VERSION ""

NS_ :

BS_:

BU_: ACM AMP BCM DIAG_TEST EMCM ESEM ETM HMSM IPC LBSS RBSS TBM TTM
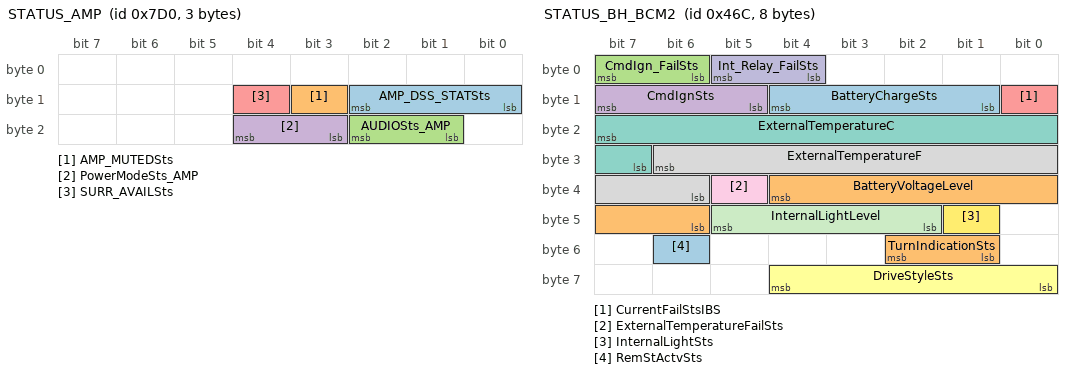
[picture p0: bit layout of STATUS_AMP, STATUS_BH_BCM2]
BO_ 2000 STATUS_AMP: 3 AMP
 SG_ AMP_DSS_STATSts : 10|3@0+ (1,0) [0|7] "" ETM
 SG_ AMP_MUTEDSts : 11|1@0+ (1,0) [0|1] "" ETM
 SG_ AUDIOSts_AMP : 18|2@0+ (1,0) [0|3] "" ETM
 SG_ PowerModeSts_AMP : 20|2@0+ (1,0) [0|3] "" BCM
 SG_ SURR_AVAILSts : 12|1@0+ (1,0) [0|1] "" ETM

BO_ 854 STATUS_BH_BCM1: 8 BCM
 SG_ BonnetSts : 26|1@0+ (1,0) [0|1] "-" ETM,IPC
 SG_ BrakeFluidLevelSts : 25|1@0+ (1,0) [0|1] "-" ETM
 SG_ BrakePadWearSts : 43|1@0+ (1,0) [0|1] "-" IPC
 SG_ BrakePedalSwitchNOSts : 36|1@0+ (1,0) [0|1] "-" ETM
 SG_ DoorLockLastElSts : 57|2@0+ (1,0) [0|3] "" ETM
 SG_ DriverDoorSts : 31|1@0+ (1,0) [0|1] "-" ACM,ETM,HMSM,IPC
 SG_ ESLLockFailSts_Indication : 55|1@0+ (1,0) [0|1] "-" IPC
 SG_ ESLUnlockFailSts_Indication : 54|1@0+ (1,0) [0|1] "-" IPC
 SG_ FrontWiperMoveSts : 42|1@0+ (1,0) [0|1] "" ACM
 SG_ FuelLevel : 7|8@0+ (1,0) [0|255] "%" ETM
 SG_ FuelLevelFailSts : 15|1@0+ (1,0) [0|1] "-" ETM
 SG_ FWindShieldFailSts : 51|1@0+ (1,0) [0|1] "-" IPC
 SG_ IMMOCodeWarningLightSts : 14|7@0+ (1,0) [0|18] "-" IPC
 SG_ LHRDoorSts : 29|1@0+ (1,0) [0|1] "-" ACM,ETM,IPC
 SG_ LowFuelWarningSts : 39|1@0+ (1,0) [0|1] "-" IPC
 SG_ MoveWheelSts : 52|1@0+ (1,0) [0|1] "-" IPC
 SG_ NightAndDaySensorFailSts : 33|1@0+ (1,0) [0|1] "" IPC
 SG_ OperationalModeSts : 23|4@0+ (1,0) [0|15] "" ACM,AMP,EMCM,ESEM,ETM,HMSM,LBSS,RBSS,TBM,TTM
 SG_ ParkBrakeSts : 24|1@0+ (1,0) [0|1] "-" LBSS,RBSS
 SG_ PowerModeSts : 19|2@0+ (1,0) [0|3] "" ACM,AMP,EMCM,ESEM,ETM,TBM
 SG_ PsngrDoorSts : 30|1@0+ (1,0) [0|1] "-" ACM,ETM,IPC
 SG_ RainSensorFailSts : 38|1@0+ (1,0) [0|1] "-" IPC
 SG_ RearTrunkEnableLastElSts : 27|1@0+ (1,0) [0|1] "-" ETM
 SG_ RHatchSts : 35|1@0+ (1,0) [0|1] "-" ACM,ETM,IPC
 SG_ RHRDoorSts : 28|1@0+ (1,0) [0|1] "-" ACM,ETM,IPC
 SG_ SysEOLSts : 34|1@0+ (1,0) [0|1] "-" IPC
 SG_ WarningKeyInSts : 37|1@0+ (1,0) [0|1] "" IPC

BO_ 1132 STATUS_BH_BCM2: 8 BCM
 SG_ BatteryChargeSts : 12|4@0+ (5,40) [40|110] "%" Vector__XXX
 SG_ BatteryVoltageLevel : 36|7@0+ (0.16,0) [0|18] "Volt" ACM,LBSS,RBSS
 SG_ CmdIgn_FailSts : 7|2@0+ (1,0) [0|3] "" ACM,AMP,EMCM,ESEM,ETM,HMSM,LBSS,RBSS,TBM,TTM
 SG_ CmdIgnSts : 15|3@0+ (1,0) [0|7] "" ACM,AMP,EMCM,ESEM,ETM,HMSM,LBSS,RBSS,TBM,TTM
 SG_ CurrentFailStsIBS : 8|1@0+ (1,0) [0|1] "-" Vector__XXX
 SG_ DriveStyleSts : 60|5@0+ (1,0) [0|31] "-" ESEM,ETM,IPC
 SG_ ExternalTemperatureC : 23|9@0+ (0.5,-85) [-85|170] "°C" ACM,ETM,IPC
 SG_ ExternalTemperatureF : 30|9@0+ (1,-121) [-121|389] "°F" ETM,IPC
 SG_ ExternalTemperatureFailSts : 37|1@0+ (1,0) [0|1] "-" ACM,ETM,IPC
 SG_ Int_Relay_FailSts : 5|2@0+ (1,0) [0|3] "" Vector__XXX
 SG_ InternalLightLevel : 45|4@0+ (1,0) [0|15] "" ACM,EMCM,ETM
 SG_ InternalLightSts : 41|1@0+ (1,0) [0|1] "" ACM,EMCM,ETM,LBSS,RBSS
 SG_ RemStActvSts : 54|1@0+ (1,0) [0|1] "" ACM
 SG_ TurnIndicationSts : 50|2@0+ (1,0) [0|3] "" LBSS,RBSS

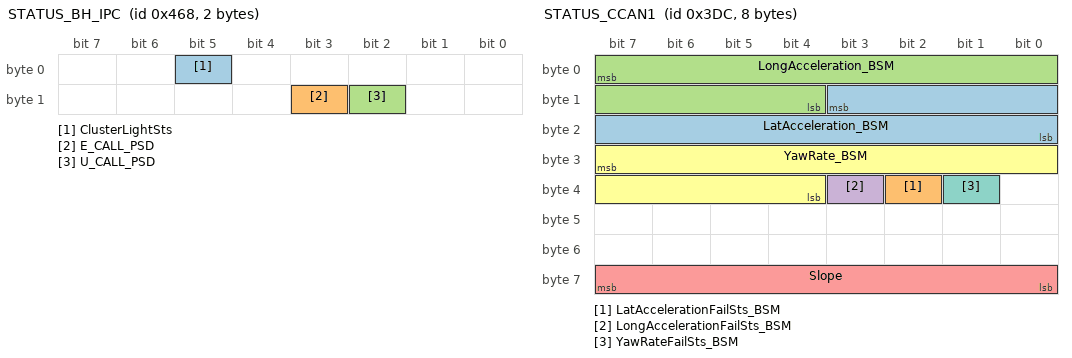
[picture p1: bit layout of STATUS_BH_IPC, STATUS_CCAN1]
BO_ 1128 STATUS_BH_IPC: 2 IPC
 SG_ ClusterLightSts : 5|1@0+ (1,0) [0|1] "" BCM
 SG_ E_CALL_PSD : 11|1@0+ (1,0) [0|1] "" ETM
 SG_ U_CALL_PSD : 10|1@0+ (1,0) [0|1] "" ETM

BO_ 988 STATUS_CCAN1: 8 BCM
 SG_ LatAcceleration_BSM : 11|12@0+ (0.02,-40.96) [-40.96|40.92] "m/s^2" ETM
 SG_ LatAccelerationFailSts_BSM : 34|1@0+ (1,0) [0|1] "-" ETM
 SG_ LongAcceleration_BSM : 7|12@0+ (0.02,-40.96) [-40.96|40.92] "m/s^2" ETM
 SG_ LongAccelerationFailSts_BSM : 35|1@0+ (1,0) [0|1] "-" ETM
 SG_ Slope : 63|8@0+ (1,-100) [-100|154] "%" ETM
 SG_ YawRate_BSM : 31|12@0+ (0.08,-163.84) [-163.84|163.68] "deg/s" ETM,LBSS,RBSS
 SG_ YawRateFailSts_BSM : 33|1@0+ (1,0) [0|1] "-" ETM,LBSS,RBSS

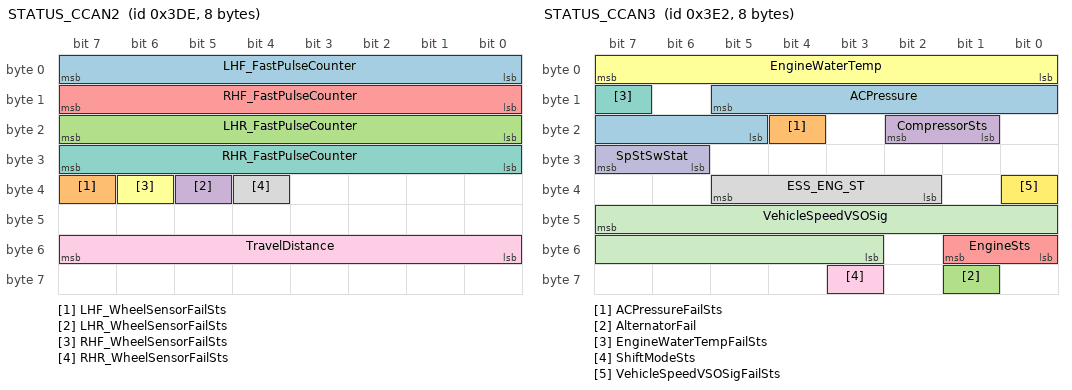
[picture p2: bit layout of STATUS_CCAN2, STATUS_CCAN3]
BO_ 990 STATUS_CCAN2: 8 BCM
 SG_ LHF_FastPulseCounter : 7|8@0+ (1,0) [0|255] "pulse" ETM
 SG_ LHF_WheelSensorFailSts : 39|1@0+ (1,0) [0|1] "-" ETM
 SG_ LHR_FastPulseCounter : 23|8@0+ (1,0) [0|255] "pulse" ETM
 SG_ LHR_WheelSensorFailSts : 37|1@0+ (1,0) [0|1] "-" ETM
 SG_ RHF_FastPulseCounter : 15|8@0+ (1,0) [0|255] "pulse" ETM
 SG_ RHF_WheelSensorFailSts : 38|1@0+ (1,0) [0|1] "-" ETM
 SG_ RHR_FastPulseCounter : 31|8@0+ (1,0) [0|255] "pulse" ETM
 SG_ RHR_WheelSensorFailSts : 36|1@0+ (1,0) [0|1] "-" ETM
 SG_ TravelDistance : 55|8@0+ (1,0) [0|255] "m" ETM

BO_ 994 STATUS_CCAN3: 8 BCM
 SG_ ACPressure : 13|9@0+ (0.1,0) [0|40] "bar" ACM
 SG_ ACPressureFailSts : 20|1@0+ (1,0) [0|1] "" ACM
 SG_ AlternatorFail : 57|1@0+ (1,0) [0|1] "" ACM
 SG_ CompressorSts : 18|2@0+ (1,0) [0|3] "" ACM,ETM
 SG_ EngineSts : 49|2@0+ (1,0) [0|3] "" ACM,AMP,EMCM,ESEM,ETM,HMSM,LBSS,RBSS,TBM,TTM
 SG_ EngineWaterTemp : 7|8@0+ (1,-40) [-40|215] "°C" ACM,ETM
 SG_ EngineWaterTempFailSts : 15|1@0+ (1,0) [0|1] "-" ACM,ETM
 SG_ ESS_ENG_ST : 37|4@0+ (1,0) [0|15] "" Vector__XXX
 SG_ ShiftModeSts : 59|1@0+ (1,0) [0|1] "" ETM
 SG_ SpStSwStat : 31|2@0+ (1,0) [0|3] "" Vector__XXX
 SG_ VehicleSpeedVSOSig : 47|13@0+ (0.0625,0) [0|511.9375] "Km/h" ACM,AMP,ESEM,ETM,HMSM,LBSS,RBSS,TTM
 SG_ VehicleSpeedVSOSigFailSts : 32|1@0+ (1,0) [0|1] "" ACM,AMP,ESEM,ETM,HMSM,LBSS,RBSS,TTM

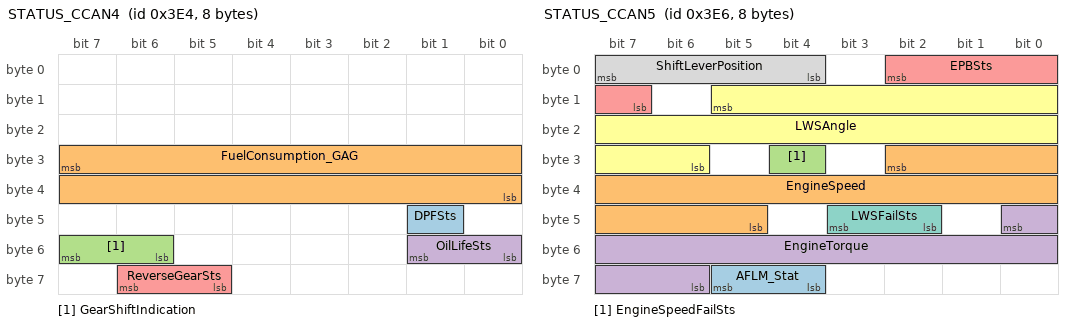
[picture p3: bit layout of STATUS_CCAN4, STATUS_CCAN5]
BO_ 996 STATUS_CCAN4: 8 BCM
 SG_ DPFSts : 41|1@0+ (1,0) [0|1] "" ETM
 SG_ FuelConsumption_GAG : 31|16@0+ (0.0022,0) [0|144.1748] "litres/hour" ETM
 SG_ GearShiftIndication : 55|2@0+ (1,0) [0|3] "-" ETM
 SG_ OilLifeSts : 49|2@0+ (1,0) [0|3] "" ETM
 SG_ ReverseGearSts : 62|2@0+ (1,0) [0|3] "" ESEM,ETM,LBSS,RBSS,TTM

BO_ 998 STATUS_CCAN5: 8 BCM
 SG_ AFLM_Stat : 61|2@0+ (1,0) [0|3] "" IPC
 SG_ EngineSpeed : 26|14@0+ (1,0) [0|16382] "1/min" ACM,ESEM,ETM
 SG_ EngineSpeedFailSts : 28|1@0+ (1,0) [0|1] "" ACM,ESEM,ETM
 SG_ EngineTorque : 40|11@0+ (1,-500) [-500|1546] "Nm" ESEM
 SG_ EPBSts : 2|4@0+ (1,0) [0|14] "" LBSS,RBSS
 SG_ LWSAngle : 13|16@0+ (0.1,-720) [-720|720] "°" ETM,LBSS,RBSS
 SG_ LWSFailSts : 43|2@0+ (1,0) [0|3] "" ETM,LBSS,RBSS
 SG_ ShiftLeverPosition : 7|4@0+ (1,0) [0|15] "" ETM,LBSS,RBSS

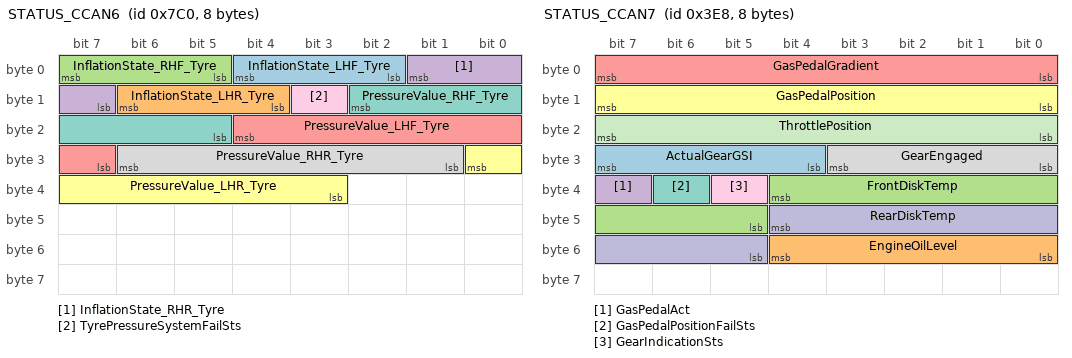
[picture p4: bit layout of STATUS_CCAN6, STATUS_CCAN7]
BO_ 1984 STATUS_CCAN6: 8 BCM
 SG_ InflationState_LHF_Tyre : 4|3@0+ (1,0) [0|4] "-" ETM
 SG_ InflationState_LHR_Tyre : 14|3@0+ (1,0) [0|4] "-" ETM
 SG_ InflationState_RHF_Tyre : 7|3@0+ (1,0) [0|4] "-" ETM
 SG_ InflationState_RHR_Tyre : 1|3@0+ (1,0) [0|4] "-" ETM
 SG_ PressureValue_LHF_Tyre : 20|6@0+ (0.1,0.7) [0.7|7] "bar" ETM
 SG_ PressureValue_LHR_Tyre : 24|6@0+ (0.1,0.7) [0.7|7] "bar" ETM
 SG_ PressureValue_RHF_Tyre : 10|6@0+ (0.1,0.7) [0.7|7] "bar" ETM
 SG_ PressureValue_RHR_Tyre : 30|6@0+ (0.1,0.7) [0.7|7] "bar" ETM
 SG_ TyrePressureSystemFailSts : 11|1@0+ (1,0) [0|1] "-" ETM

BO_ 1000 STATUS_CCAN7: 8 BCM
 SG_ ActualGearGSI : 31|4@0+ (1,0) [0|15] "-" ESEM
 SG_ EngineOilLevel : 52|5@0+ (1,0) [0|31] "-" ETM
 SG_ FrontDiskTemp : 36|8@0+ (3.13,0) [0|800] "°C" ETM
 SG_ GasPedalAct : 39|1@0+ (1,0) [0|1] "-" ESEM
 SG_ GasPedalGradient : 7|8@0+ (0.195,-25) [-25|24.53] "% /10ms" ESEM
 SG_ GasPedalPosition : 15|8@0+ (0.392,0) [0|99.568] "%" ESEM
 SG_ GasPedalPositionFailSts : 38|1@0+ (1,0) [0|1] "-" ESEM
 SG_ GearEngaged : 27|4@0+ (1,0) [0|15] "-" ESEM
 SG_ GearIndicationSts : 37|1@0+ (1,0) [0|1] "-" ESEM
 SG_ RearDiskTemp : 44|8@0+ (3.13,0) [0|800] "°C" ETM
 SG_ ThrottlePosition : 23|8@0+ (0.392,0) [0|99.96] "%" ESEM

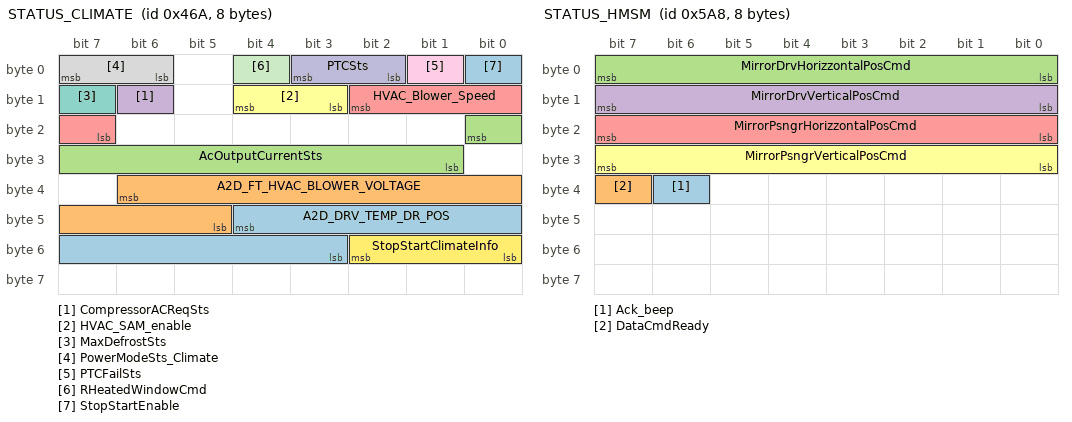
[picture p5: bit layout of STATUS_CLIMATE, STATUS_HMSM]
BO_ 1130 STATUS_CLIMATE: 8 ACM
 SG_ A2D_DRV_TEMP_DR_POS : 44|10@0+ (0.0048828125,0) [0|4.9951171875] "Volt" BCM
 SG_ A2D_FT_HVAC_BLOWER_VOLTAGE : 38|10@0+ (0.0048828125,0) [0|4.9951171875] "Volt" BCM
 SG_ AcOutputCurrentSts : 16|8@0+ (0.008,0) [0|2.04] "A" BCM
 SG_ CompressorACReqSts : 14|1@0+ (1,0) [0|1] "-" BCM
 SG_ HVAC_Blower_Speed : 10|4@0+ (1,0) [0|14] "" Vector__XXX
 SG_ HVAC_SAM_enable : 12|2@0+ (1,0) [0|3] "-" BCM
 SG_ MaxDefrostSts : 15|1@0+ (1,0) [0|1] "-" BCM
 SG_ PowerModeSts_Climate : 7|2@0+ (1,0) [0|3] "-" BCM
 SG_ PTCFailSts : 1|1@0+ (1,0) [0|1] "-" BCM
 SG_ PTCSts : 3|2@0+ (1,0) [0|3] "-" BCM
 SG_ RHeatedWindowCmd : 4|1@0+ (1,0) [0|1] "-" BCM
 SG_ StopStartClimateInfo : 50|3@0+ (1,0) [0|5] "-" BCM
 SG_ StopStartEnable : 0|1@0+ (1,0) [0|1] "-" Vector__XXX

BO_ 1482 STATUS_CLIMATE2: 8 ACM
 SG_ BlowerDisplay : 45|4@0+ (1,0) [0|15] "" ETM
 SG_ DegreeUnit : 41|1@0+ (1,0) [0|1] "" ETM
 SG_ HeatedLeft : 15|2@0+ (1,0) [0|3] "" ETM,HMSM
 SG_ HeatedRight : 13|2@0+ (1,0) [0|3] "" ETM,HMSM
 SG_ ModeDefrostLeft : 5|1@0+ (1,0) [0|1] "" ETM
 SG_ ModeDefrostRight : 2|1@0+ (1,0) [0|1] "" ETM
 SG_ ModeFloorLeft : 6|1@0+ (1,0) [0|1] "" ETM
 SG_ ModeFloorRight : 3|1@0+ (1,0) [0|1] "" ETM
 SG_ ModeVentLeft : 7|1@0+ (1,0) [0|1] "" ETM
 SG_ ModeVentRight : 4|1@0+ (1,0) [0|1] "" ETM
 SG_ OFFSts : 1|1@0+ (1,0) [0|1] "" ETM
 SG_ ShowHVACPopup : 9|2@0+ (1,0) [0|3] "" ETM
 SG_ SteeringHeatedCmd : 40|1@0+ (1,0) [0|1] "" ETM,HMSM
 SG_ TempLeftDisplay : 39|10@0+ (1,0) [0|1023] "" ETM
 SG_ TempRightDisplay : 23|10@0+ (1,0) [0|1023] "" ETM
 SG_ VentilatedLeft : 11|2@0+ (1,0) [0|3] "" ETM,HMSM
 SG_ VentilatedRight : 25|2@0+ (1,0) [0|3] "" ETM,HMSM
 SG_ WordingLeftDisplay : 29|2@0+ (1,0) [0|3] "" ETM
 SG_ WordingRightDisplay : 27|2@0+ (1,0) [0|3] "" ETM

BO_ 1454 STATUS_ESEM: 4 ESEM
 SG_ AUDIOSts_ESEM : 6|2@0+ (1,0) [0|3] "-" Vector__XXX
 SG_ PowerModeSts_ESEM : 4|2@0+ (1,0) [0|3] "-" BCM

BO_ 1448 STATUS_HMSM: 8 HMSM
 SG_ Ack_beep : 38|1@0+ (1,0) [0|1] "-" IPC
 SG_ DataCmdReady : 39|1@0+ (1,0) [0|1] "-" BCM
 SG_ MirrorDrvHorizzontalPosCmd : 7|8@0+ (1,0) [0|255] "-" BCM
 SG_ MirrorDrvVerticalPosCmd : 15|8@0+ (1,0) [0|255] "-" BCM
 SG_ MirrorPsngrHorizzontalPosCmd : 23|8@0+ (1,0) [0|255] "-" BCM
 SG_ MirrorPsngrVerticalPosCmd : 31|8@0+ (1,0) [0|255] "-" BCM

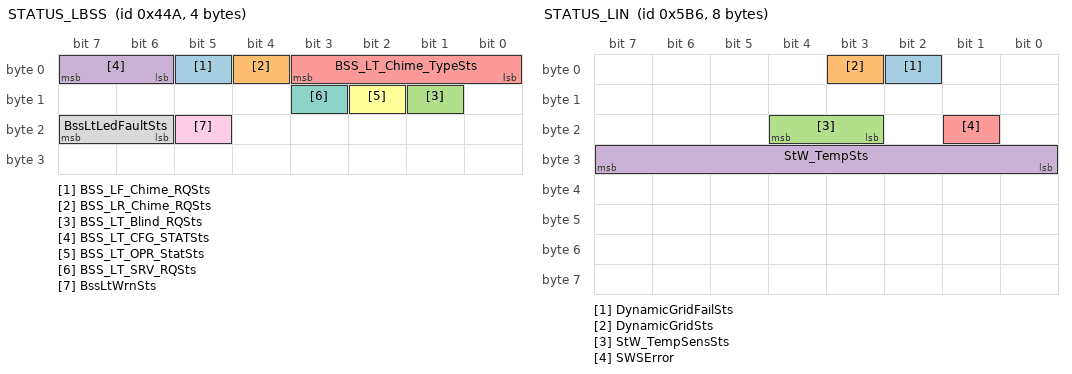
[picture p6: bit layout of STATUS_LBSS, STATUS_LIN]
BO_ 1098 STATUS_LBSS: 4 LBSS
 SG_ BSS_LF_Chime_RQSts : 5|1@0+ (1,0) [0|1] "" AMP,ETM,RBSS
 SG_ BSS_LR_Chime_RQSts : 4|1@0+ (1,0) [0|1] "" AMP,ETM,RBSS
 SG_ BSS_LT_Blind_RQSts : 9|1@0+ (1,0) [0|1] "" IPC
 SG_ BSS_LT_CFG_STATSts : 7|2@0+ (1,0) [0|2] "" AMP,ETM,IPC,RBSS
 SG_ BSS_LT_Chime_TypeSts : 3|4@0+ (1,0) [0|14] "" AMP,ETM,IPC,RBSS
 SG_ BSS_LT_OPR_StatSts : 10|1@0+ (1,0) [0|1] "" IPC
 SG_ BSS_LT_SRV_RQSts : 11|1@0+ (1,0) [0|1] "" IPC
 SG_ BssLtLedFaultSts : 23|2@0+ (1,0) [0|3] "" RBSS
 SG_ BssLtWrnSts : 21|1@0+ (1,0) [0|1] "" RBSS

BO_ 1462 STATUS_LIN: 8 BCM
 SG_ DynamicGridFailSts : 2|1@0+ (1,0) [0|1] "" ETM
 SG_ DynamicGridSts : 3|1@0+ (1,0) [0|1] "" ETM
 SG_ StW_TempSensSts : 20|2@0+ (1,0) [0|3] "" HMSM
 SG_ StW_TempSts : 31|8@0+ (0.5,-40) [-40|87] "" HMSM
 SG_ SWSError : 17|1@0+ (1,0) [0|1] "" ETM

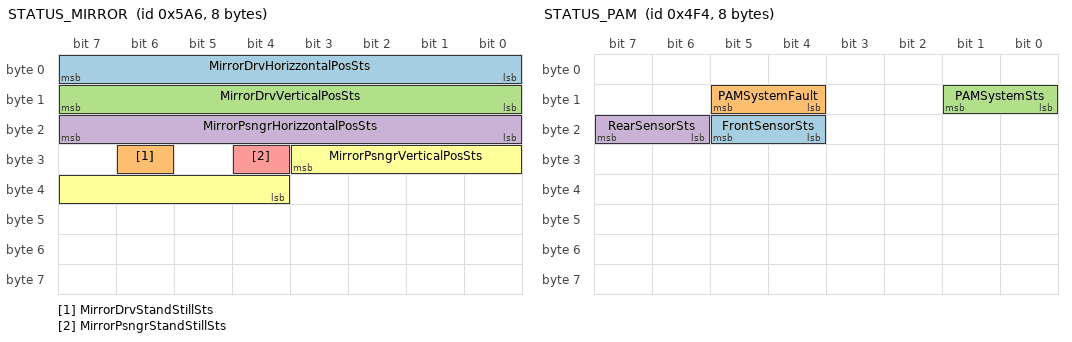
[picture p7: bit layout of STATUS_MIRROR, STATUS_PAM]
BO_ 1446 STATUS_MIRROR: 8 BCM
 SG_ MirrorDrvHorizzontalPosSts : 7|8@0+ (1,0) [0|255] "-" HMSM
 SG_ MirrorDrvStandStillSts : 30|1@0+ (1,0) [0|1] "-" HMSM
 SG_ MirrorDrvVerticalPosSts : 15|8@0+ (1,0) [0|255] "-" HMSM
 SG_ MirrorPsngrHorizzontalPosSts : 23|8@0+ (1,0) [0|255] "-" HMSM
 SG_ MirrorPsngrStandStillSts : 28|1@0+ (1,0) [0|1] "-" HMSM
 SG_ MirrorPsngrVerticalPosSts : 27|8@0+ (1,0) [0|255] "-" HMSM

BO_ 1268 STATUS_PAM: 8 BCM
 SG_ FrontSensorSts : 21|2@0+ (1,0) [0|3] "" ETM,IPC
 SG_ PAMSystemFault : 13|2@0+ (1,0) [0|3] "-" ETM,IPC
 SG_ PAMSystemSts : 9|2@0+ (1,0) [0|3] "" ETM,IPC
 SG_ RearSensorSts : 23|2@0+ (1,0) [0|3] "" ETM,IPC

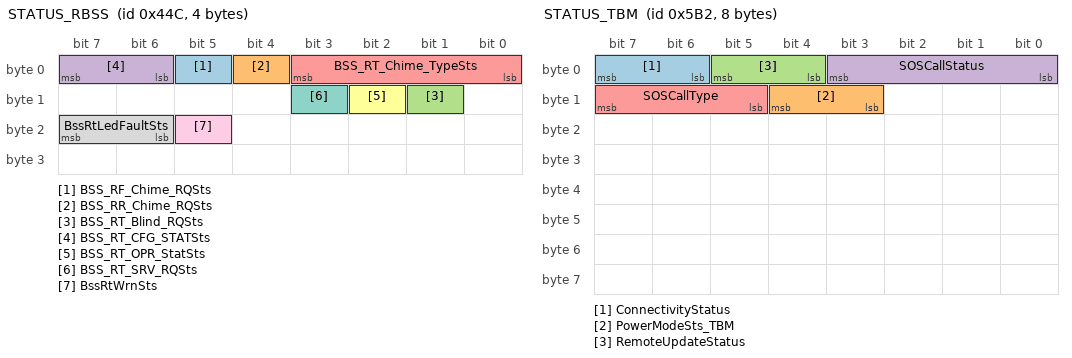
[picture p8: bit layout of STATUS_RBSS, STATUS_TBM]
BO_ 1100 STATUS_RBSS: 4 RBSS
 SG_ BSS_RF_Chime_RQSts : 5|1@0+ (1,0) [0|1] "" AMP,ETM
 SG_ BSS_RR_Chime_RQSts : 4|1@0+ (1,0) [0|1] "" AMP,ETM
 SG_ BSS_RT_Blind_RQSts : 9|1@0+ (1,0) [0|1] "" IPC
 SG_ BSS_RT_CFG_STATSts : 7|2@0+ (1,0) [0|2] "" AMP,ETM,IPC
 SG_ BSS_RT_Chime_TypeSts : 3|4@0+ (1,0) [0|14] "" AMP,ETM,IPC
 SG_ BSS_RT_OPR_StatSts : 10|1@0+ (1,0) [0|1] "" IPC
 SG_ BSS_RT_SRV_RQSts : 11|1@0+ (1,0) [0|1] "" IPC
 SG_ BssRtLedFaultSts : 23|2@0+ (1,0) [0|3] "" LBSS
 SG_ BssRtWrnSts : 21|1@0+ (1,0) [0|1] "" LBSS

BO_ 1458 STATUS_TBM: 8 TBM
 SG_ ConnectivityStatus : 7|2@0+ (1,0) [0|3] "-" ETM
 SG_ PowerModeSts_TBM : 12|2@0+ (1,0) [0|3] "-" BCM
 SG_ RemoteUpdateStatus : 5|2@0+ (1,0) [0|3] "-" Vector__XXX
 SG_ SOSCallStatus : 3|4@0+ (1,0) [0|15] "-" IPC
 SG_ SOSCallType : 15|3@0+ (1,0) [0|7] "-" Vector__XXX

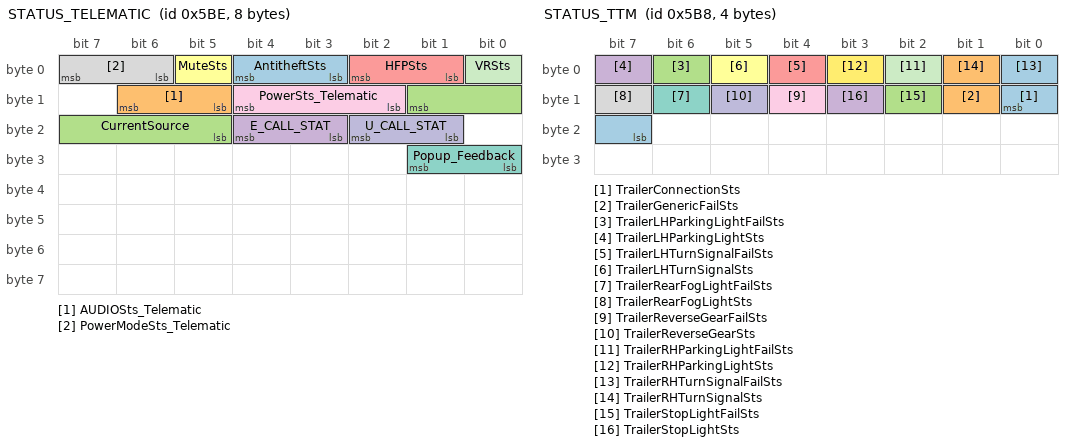
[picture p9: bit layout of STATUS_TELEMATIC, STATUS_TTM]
BO_ 1470 STATUS_TELEMATIC: 8 ETM
 SG_ AntitheftSts : 4|2@0+ (1,0) [0|3] "-" Vector__XXX
 SG_ AUDIOSts_Telematic : 14|2@0+ (1,0) [0|3] "-" AMP,BCM,IPC
 SG_ CurrentSource : 9|5@0+ (1,0) [0|31] "-" AMP
 SG_ E_CALL_STAT : 20|2@0+ (1,0) [0|3] "-" IPC
 SG_ HFPSts : 2|2@0+ (1,0) [0|3] "-" TBM
 SG_ MuteSts : 5|1@0+ (1,0) [0|1] "-" AMP
 SG_ Popup_Feedback : 25|2@0+ (1,0) [0|3] "-" ACM
 SG_ PowerModeSts_Telematic : 7|2@0+ (1,0) [0|3] "-" BCM
 SG_ PowerSts_Telematic : 12|3@0+ (1,0) [0|7] "-" Vector__XXX
 SG_ U_CALL_STAT : 18|2@0+ (1,0) [0|3] "-" IPC
 SG_ VRSts : 0|1@0+ (1,0) [0|1] "-" TBM

BO_ 1464 STATUS_TTM: 4 TTM
 SG_ TrailerConnectionSts : 8|2@0+ (1,0) [0|3] "" BCM,LBSS,RBSS
 SG_ TrailerGenericFailSts : 9|1@0+ (1,0) [0|1] "" BCM,IPC,LBSS,RBSS
 SG_ TrailerLHParkingLightFailSts : 6|1@0+ (1,0) [0|1] "" IPC
 SG_ TrailerLHParkingLightSts : 7|1@0+ (1,0) [0|1] "" Vector__XXX
 SG_ TrailerLHTurnSignalFailSts : 4|1@0+ (1,0) [0|1] "" BCM,IPC
 SG_ TrailerLHTurnSignalSts : 5|1@0+ (1,0) [0|1] "" Vector__XXX
 SG_ TrailerRearFogLightFailSts : 14|1@0+ (1,0) [0|1] "" Vector__XXX
 SG_ TrailerRearFogLightSts : 15|1@0+ (1,0) [0|1] "" Vector__XXX
 SG_ TrailerReverseGearFailSts : 12|1@0+ (1,0) [0|1] "" Vector__XXX
 SG_ TrailerReverseGearSts : 13|1@0+ (1,0) [0|1] "" Vector__XXX
 SG_ TrailerRHParkingLightFailSts : 2|1@0+ (1,0) [0|1] "" IPC
 SG_ TrailerRHParkingLightSts : 3|1@0+ (1,0) [0|1] "" Vector__XXX
 SG_ TrailerRHTurnSignalFailSts : 0|1@0+ (1,0) [0|1] "" BCM,IPC
 SG_ TrailerRHTurnSignalSts : 1|1@0+ (1,0) [0|1] "" Vector__XXX
 SG_ TrailerStopLightFailSts : 10|1@0+ (1,0) [0|1] "" IPC
 SG_ TrailerStopLightSts : 11|1@0+ (1,0) [0|1] "" Vector__XXX

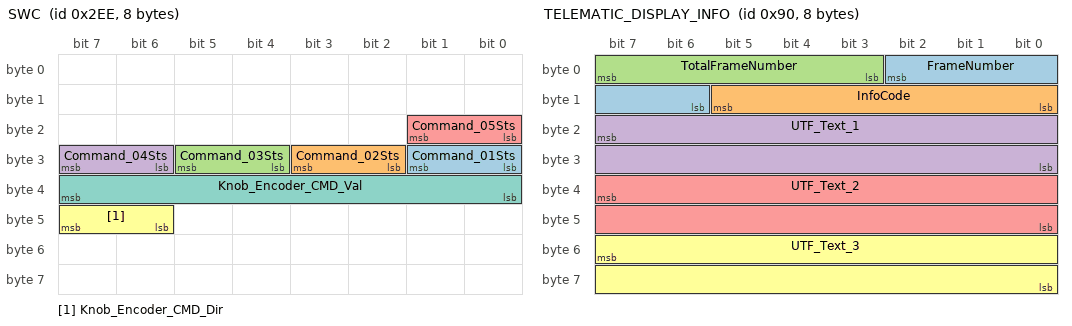
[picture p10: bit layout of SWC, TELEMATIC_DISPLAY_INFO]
BO_ 750 SWC: 8 BCM
 SG_ Command_01Sts : 25|2@0+ (1,0) [0|2] "" ETM
 SG_ Command_02Sts : 27|2@0+ (1,0) [0|2] "" ETM
 SG_ Command_03Sts : 29|2@0+ (1,0) [0|2] "" ETM
 SG_ Command_04Sts : 31|2@0+ (1,0) [0|2] "" ETM
 SG_ Command_05Sts : 17|2@0+ (1,0) [0|2] "" ETM
 SG_ Knob_Encoder_CMD_Dir : 47|2@0+ (1,0) [0|2] "" ETM
 SG_ Knob_Encoder_CMD_Val : 39|8@0+ (1,0) [0|255] "" ETM

BO_ 144 TELEMATIC_DISPLAY_INFO: 8 ETM
 SG_ FrameNumber : 2|5@0+ (1,0) [0|31] "-" IPC
 SG_ InfoCode : 13|6@0+ (1,0) [0|63] "-" IPC
 SG_ TotalFrameNumber : 7|5@0+ (1,0) [0|31] "-" IPC
 SG_ UTF_Text_1 : 23|16@0+ (1,0) [0|65535] "-" IPC
 SG_ UTF_Text_2 : 39|16@0+ (1,0) [0|65535] "-" IPC
 SG_ UTF_Text_3 : 55|16@0+ (1,0) [0|65535] "-" IPC

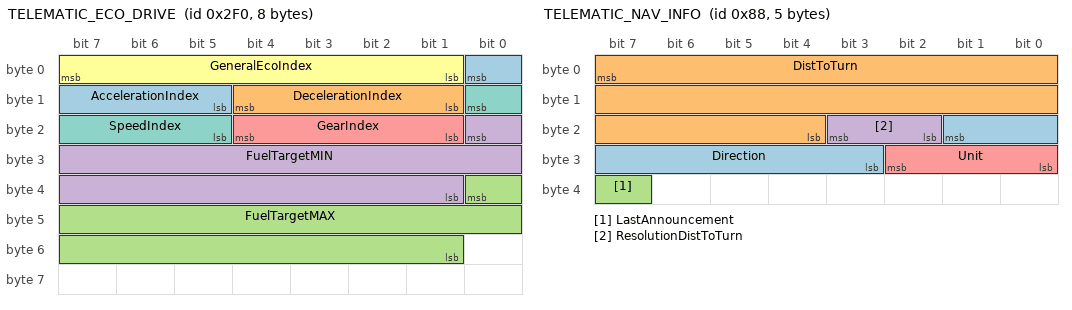
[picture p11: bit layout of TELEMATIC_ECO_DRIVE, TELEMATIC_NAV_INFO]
BO_ 752 TELEMATIC_ECO_DRIVE: 8 ETM
 SG_ AccelerationIndex : 0|4@0+ (1,0) [0|15] "-" IPC
 SG_ DecelerationIndex : 12|4@0+ (1,0) [0|15] "-" IPC
 SG_ FuelTargetMAX : 32|16@0+ (0.0022,0) [0|144.1748] "-" IPC
 SG_ FuelTargetMIN : 16|16@0+ (0.0022,0) [0|144.1748] "-" IPC
 SG_ GearIndex : 20|4@0+ (1,0) [0|15] "-" IPC
 SG_ GeneralEcoIndex : 7|7@0+ (1,0) [0|127] "-" IPC
 SG_ SpeedIndex : 8|4@0+ (1,0) [0|15] "-" Vector__XXX

BO_ 136 TELEMATIC_NAV_INFO: 5 ETM
 SG_ Direction : 17|7@0+ (1,0) [0|127] "-" IPC
 SG_ DistToTurn : 7|20@0+ (1,0) [0|1048575] "-" IPC
 SG_ LastAnnouncement : 39|1@0+ (1,0) [0|1] "-" IPC
 SG_ ResolutionDistToTurn : 19|2@0+ (1,0) [0|2] "-" IPC
 SG_ Unit : 26|3@0+ (1,0) [0|6] "-" IPC

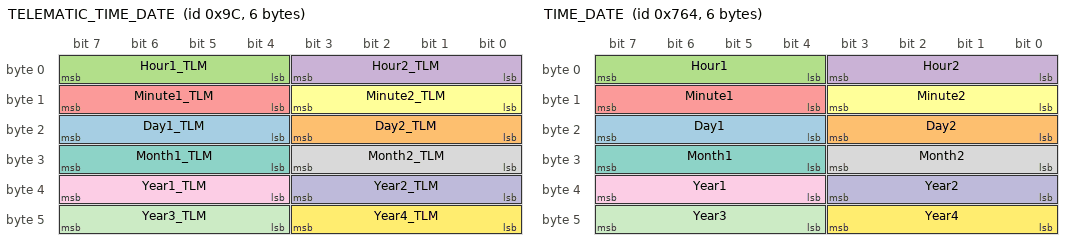
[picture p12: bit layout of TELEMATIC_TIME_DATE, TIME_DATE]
BO_ 156 TELEMATIC_TIME_DATE: 6 ETM
 SG_ Day1_TLM : 23|4@0+ (1,0) [0|3] "-" IPC
 SG_ Day2_TLM : 19|4@0+ (1,0) [0|9] "-" IPC
 SG_ Hour1_TLM : 7|4@0+ (1,0) [0|2] "-" IPC
 SG_ Hour2_TLM : 3|4@0+ (1,0) [0|9] "-" IPC
 SG_ Minute1_TLM : 15|4@0+ (1,0) [0|5] "-" IPC
 SG_ Minute2_TLM : 11|4@0+ (1,0) [0|9] "-" IPC
 SG_ Month1_TLM : 31|4@0+ (1,0) [0|1] "-" IPC
 SG_ Month2_TLM : 27|4@0+ (1,0) [0|9] "-" IPC
 SG_ Year1_TLM : 39|4@0+ (1,0) [0|2] "-" IPC
 SG_ Year2_TLM : 35|4@0+ (1,0) [0|9] "-" IPC
 SG_ Year3_TLM : 47|4@0+ (1,0) [0|9] "-" IPC
 SG_ Year4_TLM : 43|4@0+ (1,0) [0|9] "-" IPC

BO_ 158 TELEMATIC_VEHICLE_SETUP: 8 ETM
 SG_ AmbientLightingLevel_Req : 50|4@0+ (1,0) [0|15] "" IPC
 SG_ AudioRepetition_Req : 46|1@0+ (1,0) [0|1] "" IPC
 SG_ AutoHighBeamEnable_Req : 21|1@0+ (1,0) [0|1] "-" IPC
 SG_ AutomaticResetTripB_Req : 39|2@0+ (1,0) [0|3] "" Vector__XXX
 SG_ AutoParkBrake_Req : 33|1@0+ (1,0) [0|1] "" IPC
 SG_ AutoRelock_Req : 51|1@0+ (1,0) [0|1] "" IPC
 SG_ BSDEnable_Req : 30|2@0+ (1,0) [0|2] "-" IPC
 SG_ ConsumptionUnit_Req : 15|3@0+ (1,0) [0|3] "-" IPC
 SG_ CorneringEnable_Req : 18|1@0+ (1,0) [0|1] "-" IPC
 SG_ DistanceUnit_Req : 10|1@0+ (1,0) [0|1] "-" IPC
 SG_ DRLEnable_Req : 12|1@0+ (1,0) [0|1] "-" IPC
 SG_ DynamicGrid_Req : 24|1@0+ (1,0) [0|1] "" BCM
 SG_ ExternalLightSensorLevel_Req : 9|2@0+ (1,0) [0|3] "-" IPC
 SG_ GreetingLightsEnable_Req : 11|1@0+ (1,0) [0|1] "-" IPC
 SG_ HourMode_Req : 23|1@0+ (1,0) [0|1] "-" IPC
 SG_ LanguageSelection_Req : 7|8@0+ (1,0) [0|255] "-" EMCM,IPC
 SG_ NavigationRepetition_Req : 32|1@0+ (1,0) [0|1] "" IPC
 SG_ PamAlertMode_Req : 43|2@0+ (1,0) [0|3] "" IPC
 SG_ PamChimeVolumeFront_Req : 45|2@0+ (1,0) [0|3] "" IPC
 SG_ PamChimeVolumeRear_Req : 41|2@0+ (1,0) [0|3] "" IPC
 SG_ PassiveEntry_Req : 28|1@0+ (1,0) [0|1] "" IPC
 SG_ PhoneRepetition_Req : 47|1@0+ (1,0) [0|1] "" IPC
 SG_ RemoteDoorUnlock_Req : 34|1@0+ (1,0) [0|1] "" IPC
 SG_ ResetTripA_Req : 16|1@0+ (1,0) [0|1] "-" IPC
 SG_ ResetTripB_Req : 31|1@0+ (1,0) [0|1] "-" IPC
 SG_ SoundHornLock_Req : 37|2@0+ (1,0) [0|3] "" IPC
 SG_ SoundHornRemoteStart_Req : 35|1@0+ (1,0) [0|1] "" IPC
 SG_ SpeedLockDoorEnable_Req : 20|1@0+ (1,0) [0|1] "-" IPC
 SG_ TemperatureUnit_Req : 19|1@0+ (1,0) [0|1] "-" IPC
 SG_ Trip_B_Enable_Req : 17|1@0+ (1,0) [0|1] "-" IPC

BO_ 162 TELEMATIC_VEHICLE_SETUP2: 8 ETM
 SG_ AutoUnlockDoorExit_Req : 5|1@0+ (1,0) [0|1] "-" IPC
 SG_ BrakeService_Req : 16|1@0+ (1,0) [0|1] "-" IPC
 SG_ BuzzerVolume_Req : 55|2@0+ (1,0) [0|3] "-" IPC
 SG_ CalibrationSetup_Req : 44|1@0+ (1,0) [0|1] "-" IPC
 SG_ EPB_MaintenanceMode_Req : 7|1@0+ (1,0) [0|1] "-" IPC
 SG_ FlashLightWLock_Req : 6|1@0+ (1,0) [0|1] "-" IPC
 SG_ FrontPassengerAirBag_Req : 21|2@0+ (1,0) [0|3] "-" IPC
 SG_ FSFCWPlusActivationMode_Req : 23|2@0+ (1,0) [0|3] "-" IPC
 SG_ FSFCWPlusSetting_Req : 10|3@0+ (1,0) [0|7] "-" IPC
 SG_ HeadlightsOffDelay_Req : 4|2@0+ (1,0) [0|3] "-" IPC
 SG_ HHDisabling_Req : 27|1@0+ (1,0) [0|1] "-" IPC
 SG_ LDW_Sensibility_Req : 0|2@0+ (1,0) [0|3] "-" IPC
 SG_ SeatBeltReminder_Req : 17|1@0+ (1,0) [0|1] "-" IPC
 SG_ SpeedLimitSet_Req : 38|8@0+ (1,0) [0|255] "km/h" IPC
 SG_ SpeedLimitSts_Req : 46|1@0+ (1,0) [0|1] "-" IPC
 SG_ TyrePressureUnit_Req : 2|2@0+ (1,0) [0|3] "-" IPC
 SG_ Units_Req : 12|2@0+ (1,0) [0|3] "-" IPC
 SG_ VarianceSet_Req : 43|4@0+ (1,0) [0|15] "-" IPC

BO_ 1892 TIME_DATE: 6 IPC
 SG_ Day1 : 23|4@0+ (1,0) [0|9] "-" ACM,BCM,ETM,TBM
 SG_ Day2 : 19|4@0+ (1,0) [0|9] "-" ACM,BCM,ETM,TBM
 SG_ Hour1 : 7|4@0+ (1,0) [0|9] "-" ACM,BCM,ETM,TBM
 SG_ Hour2 : 3|4@0+ (1,0) [0|9] "-" ACM,BCM,ETM,TBM
 SG_ Minute1 : 15|4@0+ (1,0) [0|9] "-" BCM,ETM,TBM
 SG_ Minute2 : 11|4@0+ (1,0) [0|9] "-" BCM,ETM,TBM
 SG_ Month1 : 31|4@0+ (1,0) [0|9] "-" ACM,BCM,ETM,TBM
 SG_ Month2 : 27|4@0+ (1,0) [0|9] "-" ACM,BCM,ETM,TBM
 SG_ Year1 : 39|4@0+ (1,0) [0|9] "-" ACM,BCM,ETM,TBM
 SG_ Year2 : 35|4@0+ (1,0) [0|9] "-" ACM,BCM,ETM,TBM
 SG_ Year3 : 47|4@0+ (1,0) [0|9] "-" ACM,BCM,ETM,TBM
 SG_ Year4 : 43|4@0+ (1,0) [0|9] "-" ACM,BCM,ETM,TBM

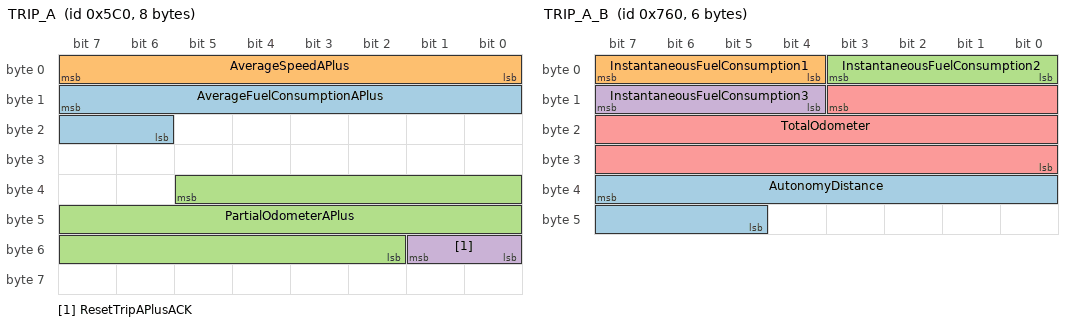
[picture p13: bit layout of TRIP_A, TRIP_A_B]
BO_ 1472 TRIP_A: 8 IPC
 SG_ AverageFuelConsumptionAPlus : 15|10@0+ (0.1,0) [0|102.3] "km/l or l/100km" ETM
 SG_ AverageSpeedAPlus : 7|8@0+ (1,0) [0|255] "km/h or mph" ETM
 SG_ PartialOdometerAPlus : 37|20@0+ (0.1,0) [0|104857.5] "km or mi." ETM
 SG_ ResetTripAPlusACK : 49|2@0+ (1,0) [0|3] "-" ETM

BO_ 1888 TRIP_A_B: 6 IPC
 SG_ AutonomyDistance : 39|11@0+ (1,0) [0|2047] "km" ETM
 SG_ InstantaneousFuelConsumption1 : 7|4@0+ (1,0) [0|15] "-" ETM
 SG_ InstantaneousFuelConsumption2 : 3|4@0+ (1,0) [0|15] "-" ETM
 SG_ InstantaneousFuelConsumption3 : 15|4@0+ (1,0) [0|15] "-" ETM
 SG_ TotalOdometer : 11|20@0+ (1,0) [0|1048575] "km" ACM,AMP,EMCM,ESEM,ETM,HMSM,LBSS,RBSS,TBM,TTM

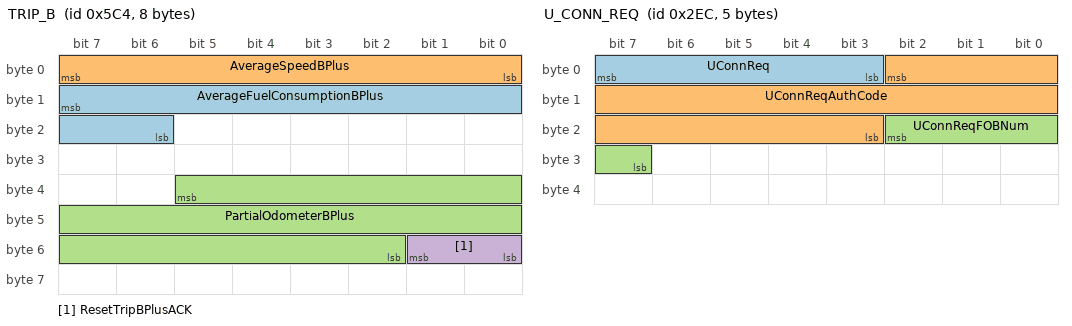
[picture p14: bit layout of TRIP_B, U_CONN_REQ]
BO_ 1476 TRIP_B: 8 IPC
 SG_ AverageFuelConsumptionBPlus : 15|10@0+ (0.1,0) [0|102.3] "km/l or l/100km" ETM
 SG_ AverageSpeedBPlus : 7|8@0+ (1,0) [0|255] "km/h or mph" ETM
 SG_ PartialOdometerBPlus : 37|20@0+ (0.1,0) [0|104857.5] "km or mi." ETM
 SG_ ResetTripBPlusACK : 49|2@0+ (1,0) [0|3] "-" ETM

BO_ 748 U_CONN_REQ: 5 ETM
 SG_ UConnReq : 7|5@0+ (1,0) [0|31] "-" BCM
 SG_ UConnReqAuthCode : 2|16@0+ (1,0) [0|65535] "-" BCM
 SG_ UConnReqFOBNum : 18|4@0+ (1,0) [0|15] "-" BCM

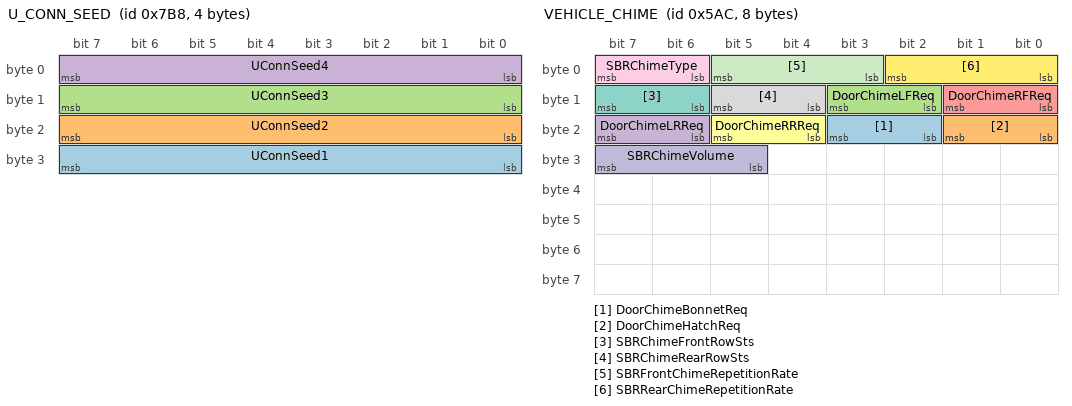
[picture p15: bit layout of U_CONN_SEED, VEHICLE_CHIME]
BO_ 1976 U_CONN_SEED: 4 BCM
 SG_ UConnSeed1 : 31|8@0+ (1,0) [0|255] "" ETM
 SG_ UConnSeed2 : 23|8@0+ (1,0) [0|255] "" ETM
 SG_ UConnSeed3 : 15|8@0+ (1,0) [0|255] "" ETM
 SG_ UConnSeed4 : 7|8@0+ (1,0) [0|255] "" ETM

BO_ 1452 VEHICLE_CHIME: 8 IPC
 SG_ DoorChimeBonnetReq : 19|2@0+ (1,0) [0|3] "-" AMP,ETM
 SG_ DoorChimeHatchReq : 17|2@0+ (1,0) [0|3] "-" AMP,ETM
 SG_ DoorChimeLFReq : 11|2@0+ (1,0) [0|3] "-" AMP,ETM
 SG_ DoorChimeLRReq : 23|2@0+ (1,0) [0|3] "-" AMP,ETM
 SG_ DoorChimeRFReq : 9|2@0+ (1,0) [0|3] "-" AMP,ETM
 SG_ DoorChimeRRReq : 21|2@0+ (1,0) [0|3] "-" AMP,ETM
 SG_ SBRChimeFrontRowSts : 15|2@0+ (1,0) [0|3] "-" AMP,ETM
 SG_ SBRChimeRearRowSts : 13|2@0+ (1,0) [0|3] "-" AMP,ETM
 SG_ SBRChimeType : 7|2@0+ (1,0) [0|3] "-" AMP,ETM
 SG_ SBRChimeVolume : 31|3@0+ (1,0) [0|7] "-" AMP,ETM
 SG_ SBRFrontChimeRepetitionRate : 5|3@0+ (1,0) [0|7] "-" AMP,ETM
 SG_ SBRRearChimeRepetitionRate : 2|3@0+ (1,0) [0|7] "-" AMP,ETM

BO_ 992 VIN: 8 BCM
 SG_ VIN_DATA : 15|56@0+ (1,0) [0|7.20575940379279E+16] "" ACM,AMP,EMCM,ESEM,ETM,HMSM,LBSS,RBSS,TBM,TTM
 SG_ VIN_MSG : 1|2@0+ (1,0) [0|3] "" ACM,AMP,EMCM,ESEM,ETM,HMSM,LBSS,RBSS,TBM,TTM

CM_ SG_ 2000 AMP_DSS_STATSts "Driver Select Surround Status";
CM_ SG_ 2000 AMP_MUTEDSts "Amplifer mute status; unmuted = [0], muted = [1]";
CM_ SG_ 2000 AUDIOSts_AMP "Used to give information about Telematic Module audio availability";
CM_ SG_ 2000 SURR_AVAILSts "Surround sound available for selected cabin mode; [1] = True";
CM_ SG_ 854 BonnetSts "Used to indicate the status of the bonnet";
CM_ SG_ 854 BrakePadWearSts "The signals indicates the brake pad wear sts";
CM_ SG_ 854 BrakePedalSwitchNOSts "It is the Brake Light Switch (Normally Open) position status, acquired by BCM and transmitted on CAN.";
CM_ SG_ 854 DoorLockLastElSts "Reports the last knonw eletrical request for the doors to lock or unlock.";
CM_ SG_ 854 DriverDoorSts "Used to indicate the status of driver door";
CM_ SG_ 854 ESLLockFailSts_Indication "This signal is used to give information about a failure of the ESL during a lock procedure.";
CM_ SG_ 854 ESLUnlockFailSts_Indication "This signal is used to give information about a failure of the ESL during an unlock procedure.";
CM_ SG_ 854 FrontWiperMoveSts "This signal indicates the position of the front wiper (contact cam open or close).";
CM_ SG_ 854 FuelLevel "Used to give information about the percentage of the fuel level present in the tank.";
CM_ SG_ 854 FuelLevelFailSts "Used to give information about the fail status of the FuelLevel signal.";
CM_ SG_ 854 FWindShieldFailSts "The signals indicates the Status of Wind Shield";
CM_ SG_ 854 LHRDoorSts "Used to indicate the status of left rear door";
CM_ SG_ 854 LowFuelWarningSts "Used to give information about the status of the low fuel warning.";
CM_ SG_ 854 MoveWheelSts "This signal is used to give a message to the customer to move the steering wheel.";
CM_ SG_ 854 ParkBrakeSts "Status of Park Brake";
CM_ SG_ 854 PsngrDoorSts "Used to indicate the status of passenger door";
CM_ SG_ 854 RainSensorFailSts "This signal indicates a Rain sensor fail.";
CM_ SG_ 854 RearTrunkEnableLastElSts "It specifies the electric status of the rear trunk switch";
CM_ SG_ 854 RHatchSts "Used to indicate the status of the trunk liftgate";
CM_ SG_ 854 RHRDoorSts "Used to indicate the status of right rear door";
CM_ SG_ 854 WarningKeyInSts "This signal activates a buzzer when the driver door is open and the key is in the starting system.";
CM_ SG_ 1132 BatteryChargeSts "Battery State of Charge (in %), as acquired from the battery sensor";
CM_ SG_ 1132 BatteryVoltageLevel "This signal is used to indicate the voltage level of the battery";
CM_ SG_ 1132 CmdIgnSts "Used to give information about the key selector position";
CM_ SG_ 1132 CurrentFailStsIBS "It signals a possible fault of the battery sensor";
CM_ SG_ 1132 DriveStyleSts "This signal gives indications about drive style status required.";
CM_ SG_ 1132 ExternalTemperatureC "Used to indicate the external temperature value in °C";
CM_ SG_ 1132 ExternalTemperatureF "Used to indicate the external temperature value in °F";
CM_ SG_ 1132 ExternalTemperatureFailSts "Used to indicate if a Fail is present for the external temperature value";
CM_ SG_ 1132 InternalLightLevel "Used to give information about the backlight dimming level selected.";
CM_ SG_ 1132 InternalLightSts "Used to give information about backlight mode selected (Day or Night).";
CM_ SG_ 1132 RemStActvSts "Ignition Run active for remote start";
CM_ SG_ 1128 ClusterLightSts "Used to give information about the status of the cluster light sensor.";
CM_ SG_ 1128 E_CALL_PSD "E-call buttom pressed on ECMM =1:pressed";
CM_ SG_ 1128 U_CALL_PSD "U-call buttom pressed on ECMM =1:pressed";
CM_ SG_ 988 LatAcceleration_BSM "This signal indicates the Lateral Acceleration Value";
CM_ SG_ 988 LatAccelerationFailSts_BSM "This signal indicates the status of Lateral Acceleration Signal";
CM_ SG_ 988 LongAcceleration_BSM "This signal indicates the Longitudinal Acceleration Value";
CM_ SG_ 988 LongAccelerationFailSts_BSM "This signal indicates the status of Longitudinal acceleration signal";
CM_ SG_ 988 Slope "Slope value detected by BSM";
CM_ SG_ 988 YawRate_BSM "This signal indicates the Yaw Rate Value";
CM_ SG_ 988 YawRateFailSts_BSM "This signal indicates the Status of Yaw Rate Signal";
CM_ SG_ 990 LHF_FastPulseCounter "This signal is the left front wheel pulse counter.";
CM_ SG_ 990 LHF_WheelSensorFailSts "This signal indicates the fail status of LHF sensor";
CM_ SG_ 990 LHR_FastPulseCounter "This signal is the left rear wheel pulse counter.";
CM_ SG_ 990 LHR_WheelSensorFailSts "This signal indicates the fail status of LHR sensor";
CM_ SG_ 990 RHF_FastPulseCounter "This signal is the right front wheel pulse counter.";
CM_ SG_ 990 RHF_WheelSensorFailSts "This signal indicates the fail status of RHF sensor";
CM_ SG_ 990 RHR_FastPulseCounter "This signal is the right rear wheel pulse counter.";
CM_ SG_ 990 RHR_WheelSensorFailSts "This signal indicates the fail status of RHR sensor";
CM_ SG_ 990 TravelDistance "This signal indicates the travel distance value.";
CM_ SG_ 994 ACPressure "It indicates air conditioning pressure read from the AC linear pressure sensor.";
CM_ SG_ 994 ACPressureFailSts "This signal indicates if the ACpressure sensor is in fail.";
CM_ SG_ 994 AlternatorFail "Indicates if the alternator is in fail condition";
CM_ SG_ 994 CompressorSts "This signal gives information about the present status of A/C external request and actual A/C activation by ECM.";
CM_ SG_ 994 EngineSts "It is the current engine status";
CM_ SG_ 994 EngineWaterTemp "It is the engine water temperature, measured through the related sensor.";
CM_ SG_ 994 EngineWaterTempFailSts "It is the Fail Status bit of EngineWaterTemp signal; the signal is set to Fail Present when the engine temperature sensor is faulty.";
CM_ SG_ 994 ESS_ENG_ST "ESS Engine State";
CM_ SG_ 994 ShiftModeSts "This signal indicates the gear selector modality selected by driver (Manual or Automatic).";
CM_ SG_ 994 SpStSwStat "Stop start switch status";
CM_ SG_ 994 VehicleSpeedVSOSig "It is the average vehicle speed calculated.";
CM_ SG_ 994 VehicleSpeedVSOSigFailSts "It is the average vehicle speed fail status.";
CM_ SG_ 996 DPFSts "It is required only on diesel systems equipped with Diesel Particulate Filter. It is used to signalize that the current operating conditions (engine load, DPF pressure and temperature) do not allow performing the DPF regeneration strategy (signa(...)";
CM_ SG_ 996 FuelConsumption_GAG "It represents instantaneous consumption information sent on network";
CM_ SG_ 996 GearShiftIndication "It gives indication of gear shifting";
CM_ SG_ 996 OilLifeSts "This information is related to engine oil life algorithm, currently used on Diesel engines equipped with DPF.";
CM_ SG_ 996 ReverseGearSts "It gives information of reverse gear status.";
CM_ SG_ 998 AFLM_Stat "This signal indicates the status AFLM faults";
CM_ SG_ 998 EngineSpeed "Used to indicate the engine speed";
CM_ SG_ 998 EngineSpeedFailSts "Used to indicate if a Fail is present for the engine speed";
CM_ SG_ 998 EngineTorque "This signal represents engine torque expressed as flywheel torque. This torque can have only positive values. It is the actual value currently given by the engine";
CM_ SG_ 1984 InflationState_LHF_Tyre "It signal indicated the state for the pressure of the wheel identified";
CM_ SG_ 1984 InflationState_LHR_Tyre "It signal indicated the state for the pressure of the wheel identified";
CM_ SG_ 1984 InflationState_RHF_Tyre "It signal indicated the state for the pressure of the wheel identified";
CM_ SG_ 1984 InflationState_RHR_Tyre "It signal indicated the state for the pressure of the wheel identified";
CM_ SG_ 1984 PressureValue_LHF_Tyre "It is the value of indicated tyre wheel [bar]";
CM_ SG_ 1984 PressureValue_LHR_Tyre "It is the value of indicated tyre wheel [bar]";
CM_ SG_ 1984 PressureValue_RHF_Tyre "It is the value of indicated tyre wheel [bar]";
CM_ SG_ 1984 PressureValue_RHR_Tyre "It is the value of indicated tyre wheel [bar]";
CM_ SG_ 1984 TyrePressureSystemFailSts "It indicates that the TPM System is in Fault or not";
CM_ SG_ 1000 EngineOilLevel "Engine Oil Level";
CM_ SG_ 1000 FrontDiskTemp "The signal indicates the Front disk temperature";
CM_ SG_ 1000 GasPedalAct "This signal is active when the gas pedal is pressed, that is when the gas pedal position is greater than the idle speed recognition threshold.";
CM_ SG_ 1000 GasPedalGradient "This signal represents gradient of the gas pedal position over the transmission period.";
CM_ SG_ 1000 GasPedalPosition "This signal represents gradient of the gas pedal position over the transmission period.";
CM_ SG_ 1000 GasPedalPositionFailSts "It indicates the fail status of the signal GasPedalPisition";
CM_ SG_ 1000 GearEngaged "Current engaged gear.";
CM_ SG_ 1000 GearIndicationSts "This signal is related to the displayed gear indication (if it is blinking or not)";
CM_ SG_ 1000 RearDiskTemp "The signal indicates the Rear disk temperature";
CM_ SG_ 1000 ThrottlePosition "GASOLINE APPLICATION ONLY This signal represents throttle position evaluated on the basis of throttle position sensor.";
CM_ SG_ 1130 A2D_DRV_TEMP_DR_POS "Transmit raw A/D driver temp door position to ECM, the information is used to make OBD model more robust";
CM_ SG_ 1130 A2D_FT_HVAC_BLOWER_VOLTAGE "Transmit raw A/D blower voltage to ECM, the information is used to make OBD model more robust";
CM_ SG_ 1130 AcOutputCurrentSts "It is the ECVD electrovalve current";
CM_ SG_ 1130 CompressorACReqSts "Used to indicate the user request of compressor activation";
CM_ SG_ 1130 HVAC_Blower_Speed "The signal indicates the PWM command for Blower and blower status";
CM_ SG_ 1130 HVAC_SAM_enable "Disable the SAM if high blower speed is required";
CM_ SG_ 1130 MaxDefrostSts "Used to indicate the user request status of Max Defrost";
CM_ SG_ 1130 PTCFailSts "Used to indicate if a Fail is present for the PTC activation status";
CM_ SG_ 1130 PTCSts "Used to indicate the PTC activation status";
CM_ SG_ 1130 RHeatedWindowCmd "Used to require the Rear heated window activation/deactivation.";
CM_ SG_ 1130 StopStartClimateInfo "Stop start enable from ECC";
CM_ SG_ 1130 StopStartEnable "Sent by ECC (if present) it signals the consent by climate control to the Stop&Start function";
CM_ SG_ 1482 BlowerDisplay "This signal is used to give information about the blower value";
CM_ SG_ 1482 HeatedLeft "This signal is used to give activation about heated activation on left side";
CM_ SG_ 1482 HeatedRight "This signal is used to give activation about heated activation on right side";
CM_ SG_ 1482 ModeDefrostLeft "This signal is used to give information about the defrost mode activation on left";
CM_ SG_ 1482 ModeDefrostRight "This signal is used to give information about the defrost mode activation on right";
CM_ SG_ 1482 ModeFloorLeft "This signal is used to give information about the floor mode activation on left";
CM_ SG_ 1482 ModeFloorRight "This signal is used to give information about the floor mode activation on right";
CM_ SG_ 1482 ModeVentLeft "This signal is used to give information about the ventilation mode activation on left";
CM_ SG_ 1482 ModeVentRight "This signal is used to give information about the ventilation mode activation on right";
CM_ SG_ 1482 OFFSts "This signal is used to give information about the status";
CM_ SG_ 1482 ShowHVACPopup "This signal is used to manage the popup command on ETM";
CM_ SG_ 1482 SteeringHeatedCmd "This signal is used to manage the steerig heated command on ETM";
CM_ SG_ 1482 TempLeftDisplay "This signal is used to give information about temperature requested by Left passenger";
CM_ SG_ 1482 TempRightDisplay "This signal is used to give information about temperature requested by Right passenger";
CM_ SG_ 1482 VentilatedLeft "This signal is used to give activation about ventilation activation on left side";
CM_ SG_ 1482 VentilatedRight "This signal is used to give activation about ventilationactivation on right side";
CM_ SG_ 1482 WordingLeftDisplay "This signal is used to give information about the Auto Wording left";
CM_ SG_ 1482 WordingRightDisplay "This signal is used to give information about the Auto Wording right";
CM_ SG_ 1454 AUDIOSts_ESEM "Used to give information about Telematic Module audio availability";
CM_ SG_ 1448 Ack_beep "Feedback for Roger beep activation";
CM_ SG_ 1448 DataCmdReady "This signal is used to manage the Door Chime for Left Rear door";
CM_ SG_ 1448 MirrorDrvHorizzontalPosCmd "This signal is used to manage the Driver Mirror Horizzontal Position Command";
CM_ SG_ 1448 MirrorDrvVerticalPosCmd "This signal is used to manage the Driver Mirror Vertical Position Command";
CM_ SG_ 1448 MirrorPsngrHorizzontalPosCmd "This signal is used to manage the Passenger Mirror Horizzontal Position";
CM_ SG_ 1448 MirrorPsngrVerticalPosCmd "signal is used to manage the Passenger Mirror Vertical Position Command";
CM_ SG_ 1098 BSS_LF_Chime_RQSts "BSM left front chime on request";
CM_ SG_ 1098 BSS_LR_Chime_RQSts "BSM Left rear chime on request";
CM_ SG_ 1098 BSS_LT_Blind_RQSts "Sensor blinded request from BSS Left";
CM_ SG_ 1098 BSS_LT_CFG_STATSts "Blind Spot left Side configuration status";
CM_ SG_ 1098 BSS_LT_Chime_TypeSts "BSS left side chime type";
CM_ SG_ 1098 BSS_LT_OPR_StatSts "BSS Left Side operation status";
CM_ SG_ 1098 BSS_LT_SRV_RQSts "BSS Left Side service warning request";
CM_ SG_ 1098 BssLtLedFaultSts "Left Sensor Led fault Status";
CM_ SG_ 1098 BssLtWrnSts "Left Sensor LED Warning Status";
CM_ SG_ 1462 DynamicGridFailSts "Rear View Camera Dynamic Gridlines fail condition";
CM_ SG_ 1462 DynamicGridSts "Rear View Camera Dynamic Gridlines request";
CM_ SG_ 1462 StW_TempSensSts "Used to inform about a fault on the steering wheel temperature";
CM_ SG_ 1462 StW_TempSts "Used to inform about the steering wheel temperature";
CM_ SG_ 1446 MirrorDrvHorizzontalPosSts "This signal is used to manage the Driver Mirror Horizzontal Position Status";
CM_ SG_ 1446 MirrorDrvStandStillSts "This signal is used to manage the Driver Mirror Stand Still Status";
CM_ SG_ 1446 MirrorDrvVerticalPosSts "This signal is used to manage the Driver Mirror Vertical Position Status";
CM_ SG_ 1446 MirrorPsngrHorizzontalPosSts "This signal is used to manage the Passenger Mirror Horizzontal Position Status";
CM_ SG_ 1446 MirrorPsngrStandStillSts "This signal is used to manage the Passenger Mirror Stand Still Status";
CM_ SG_ 1446 MirrorPsngrVerticalPosSts "This signal is used to manage the Passenger Mirror Vertical Position Status";
CM_ SG_ 1268 FrontSensorSts "This signal indicates the activation state of the front sensors.";
CM_ SG_ 1268 PAMSystemFault "This signal indicates if the PAM is in a faulted condition";
CM_ SG_ 1268 PAMSystemSts "This signal indicates the activation state of the PAM";
CM_ SG_ 1268 RearSensorSts "This signal indicates the activation state of the rear sensors";
CM_ SG_ 1100 BSS_RF_Chime_RQSts "BSM right front chime on request";
CM_ SG_ 1100 BSS_RR_Chime_RQSts "BSM right rear chime on request";
CM_ SG_ 1100 BSS_RT_Blind_RQSts "Sensor blinded request from BSS Right";
CM_ SG_ 1100 BSS_RT_CFG_STATSts "Blind Spot Right Side configuration status";
CM_ SG_ 1100 BSS_RT_Chime_TypeSts "BSS right side chime type";
CM_ SG_ 1100 BSS_RT_OPR_StatSts "BSS Right Side operation status";
CM_ SG_ 1100 BSS_RT_SRV_RQSts "BSS Right Side service warning request";
CM_ SG_ 1100 BssRtLedFaultSts "Right Sensor Led fault Status";
CM_ SG_ 1100 BssRtWrnSts "Right Sensor LED Warning Status";
CM_ SG_ 1458 ConnectivityStatus "Services and Quality Data Feed services status";
CM_ SG_ 1458 RemoteUpdateStatus "TBM module remote update status";
CM_ SG_ 1458 SOSCallStatus "SOS call function status";
CM_ SG_ 1458 SOSCallType "Type of SOS call";
CM_ SG_ 1470 AntitheftSts "ETM Antitheft logic status";
CM_ SG_ 1470 AUDIOSts_Telematic "Used to give information about Telematic Module audio availability";
CM_ SG_ 1470 CurrentSource "ETM current active source";
CM_ SG_ 1470 E_CALL_STAT "E-call status";
CM_ SG_ 1470 HFPSts "ETM hands free phone status";
CM_ SG_ 1470 MuteSts "ETM Entertainment source Mute status";
CM_ SG_ 1470 Popup_Feedback "This signal is managed to give to ACM the feedback about the screen type shown in ETM display";
CM_ SG_ 1470 PowerSts_Telematic "ETM power status";
CM_ SG_ 1470 U_CALL_STAT "E-call status";
CM_ SG_ 1470 VRSts "ETM Voice Recognition  Status";
CM_ SG_ 1464 TrailerConnectionSts "Connection status of TTM";
CM_ SG_ 1464 TrailerGenericFailSts "Status of Fail of TTM";
CM_ SG_ 1464 TrailerLHParkingLightFailSts "Status of Fail of Trailer Left Parking Light";
CM_ SG_ 1464 TrailerLHParkingLightSts "Status of Trailer Left Parking Light Output";
CM_ SG_ 1464 TrailerLHTurnSignalFailSts "Status of Fail of Trailer Left Turn Light";
CM_ SG_ 1464 TrailerLHTurnSignalSts "Status of Trailer Left Turn Light Output";
CM_ SG_ 1464 TrailerRearFogLightFailSts "Status of Fail of Trailer Rear Fog Light";
CM_ SG_ 1464 TrailerRearFogLightSts "Status of Trailer Rear Fog Light Output";
CM_ SG_ 1464 TrailerReverseGearFailSts "Status of Fail of Trailer Reverse Gear Light";
CM_ SG_ 1464 TrailerReverseGearSts "Status of Trailer Reverse Gear Light Output";
CM_ SG_ 1464 TrailerRHParkingLightFailSts "Status of Fail of Trailer Right Parking Light";
CM_ SG_ 1464 TrailerRHParkingLightSts "Status of Trailer Right Parking Light Output";
CM_ SG_ 1464 TrailerRHTurnSignalFailSts "Status of Fail of Trailer Right Turn Light";
CM_ SG_ 1464 TrailerRHTurnSignalSts "Status of Trailer Right Turn Light Output";
CM_ SG_ 1464 TrailerStopLightFailSts "Status of Fail of Trailer Stop Lights";
CM_ SG_ 1464 TrailerStopLightSts "Status of Trailer Stop Light Outputs";
CM_ SG_ 750 Command_01Sts "Infotainment Switch 1";
CM_ SG_ 750 Command_02Sts "Infotainment Switch 2";
CM_ SG_ 750 Command_03Sts "Infotainment Switch 3";
CM_ SG_ 750 Command_04Sts "Infotainment Switch 4";
CM_ SG_ 750 Command_05Sts "Infotainment Switch 5";
CM_ SG_ 750 Knob_Encoder_CMD_Dir "This signal is used to manage the Knob DIRECTION value";
CM_ SG_ 750 Knob_Encoder_CMD_Val "This signal is used to manage the absolute Knob increment/decrement VALUE value";
CM_ SG_ 752 AccelerationIndex "This signal is used to give information about instantaneous ECO ACCELERATION index";
CM_ SG_ 752 DecelerationIndex "This signal is used to give information about instantaneous ECO DECELERATION index";
CM_ SG_ 752 FuelTargetMAX "It represents Maximum consumption information sent on network";
CM_ SG_ 752 FuelTargetMIN "It represents Minimum consumption information sent on network";
CM_ SG_ 752 GearIndex "This signal is used to give information about instantaneous ECO GEAR index";
CM_ SG_ 752 GeneralEcoIndex "This signal is used to give information about instantaneous ECO index";
CM_ SG_ 752 SpeedIndex "This signal is used to give information about instantaneous ECO SPEED index";
CM_ SG_ 158 AmbientLightingLevel_Req "This signal is managed when the driver request a  setting of the Ambient Light Level";
CM_ SG_ 158 AutoHighBeamEnable_Req "This signal is managed when the driver requests a setting of  the Auto High Beam feature";
CM_ SG_ 158 AutomaticResetTripB_Req "This signal is managed when the driver requests a setting of the Automatic Reset of Trip B";
CM_ SG_ 158 AutoParkBrake_Req "This signal is managed when the driver requests a setting of the Auto Park Brake";
CM_ SG_ 158 AutoRelock_Req "This signal is managed when the driver requests a setting of the Auto Relock feature";
CM_ SG_ 158 BSDEnable_Req "This signal is managed when the driver requests a setting of Blind Spot Alert";
CM_ SG_ 158 ConsumptionUnit_Req "This signal is managed when the driver requests a setting of Consumption Unit";
CM_ SG_ 158 CorneringEnable_Req "This signal is managed when the driver requests a setting of Cornering Lights";
CM_ SG_ 158 DistanceUnit_Req "This signal is managed when the driver requests a setting of Distance Unit";
CM_ SG_ 158 DRLEnable_Req "This signal is managed when the driver requests a setting of the DRL feature";
CM_ SG_ 158 DynamicGrid_Req "Rear View Camera Dynamic Gridlines request";
CM_ SG_ 158 ExternalLightSensorLevel_Req "This signal is managed when the driver requests a setting of External Light Sensor Level";
CM_ SG_ 158 GreetingLightsEnable_Req "This signal is managed when the button of block or unblocking of the door is pressed.";
CM_ SG_ 158 HourMode_Req "This signal is managed when the driver requests a setting of Hour Mode";
CM_ SG_ 158 LanguageSelection_Req "This signal is managed when the driver requests a setting of Language";
CM_ SG_ 158 PamAlertMode_Req "This signal is managed when the driver requests a setting of the PAM Alert Mode";
CM_ SG_ 158 PamChimeVolumeFront_Req "This signal is managed when the driver request a  setting of the of Chime Volume  of the PAM";
CM_ SG_ 158 PamChimeVolumeRear_Req "This signal is managed when the driver request a  setting of the of Chime Volume  of the PAM  8  Channels";
CM_ SG_ 158 PassiveEntry_Req "This signal is managed when the driver requests a setting of the Passive Entry";
CM_ SG_ 158 RemoteDoorUnlock_Req "This signal is managed when the driver requests a setting of the Remote Door Unlock";
CM_ SG_ 158 ResetTripA_Req "This signal is managed when the driver requests a setting of the Reset of Trip A";
CM_ SG_ 158 ResetTripB_Req "This signal is managed when the driver requests a setting of the Reset of Trip B";
CM_ SG_ 158 SoundHornLock_Req "This signal is managed when the driver requests a setting of the Sound Horn with Unlock";
CM_ SG_ 158 SoundHornRemoteStart_Req "This signal is managed when the driver requests a setting of the Sound Horn with Remote Start";
CM_ SG_ 158 SpeedLockDoorEnable_Req "This signal is managed when the driver requests a setting of Auto Door Locks";
CM_ SG_ 158 TemperatureUnit_Req "This signal is managed when the driver requests a setting of Temperature Unit";
CM_ SG_ 162 AutoUnlockDoorExit_Req "This signal is managed when the driver request a setting of  Auto Unlock Door On Exit";
CM_ SG_ 162 BrakeService_Req "The signal is managed when the driver requests a setting of Brake Service";
CM_ SG_ 162 BuzzerVolume_Req "This signal is managed when the driver requests to choose the Buzzer Volume function";
CM_ SG_ 162 CalibrationSetup_Req "This signal is managed when the driver requests to active/disactive the Calibration Setup of the Compass function";
CM_ SG_ 162 EPB_MaintenanceMode_Req "This signal is managed when the driver request a setting of  Maintenance Mode";
CM_ SG_ 162 FlashLightWLock_Req "This signal is managed when the driver request a setting of  Flash Light With Lock";
CM_ SG_ 162 FrontPassengerAirBag_Req "The signal is managed when the driver requests a setting of front passenger airbag";
CM_ SG_ 162 FSFCWPlusActivationMode_Req "This signal is managed when the driver request a  setting of FSFCW";
CM_ SG_ 162 FSFCWPlusSetting_Req "This signal is managed when the driver request a  setting of FSFCW";
CM_ SG_ 162 HeadlightsOffDelay_Req "This signal is managed when the driver requests a setting of the Headligts Off Delay";
CM_ SG_ 162 HHDisabling_Req "This signal is managed when the driver requests a setting of Hill Holder";
CM_ SG_ 162 LDW_Sensibility_Req "This signal is managed when the driver requests a setting of  the LDW Sensibility";
CM_ SG_ 162 SeatBeltReminder_Req "The signal is managed when the driver requests a setting of Selt Belt Reminder";
CM_ SG_ 162 SpeedLimitSet_Req "This signal is managed when the driver requests a setting of speed limit function";
CM_ SG_ 162 SpeedLimitSts_Req "This signal is managed when the driver requests to active/disactive the speed limit function";
CM_ SG_ 162 TyrePressureUnit_Req "This signal is managed when the driver requests a setting of  the Tyre Pressure Unit";
CM_ SG_ 162 VarianceSet_Req "This signal is managed when the driver requests a Variance Set for the Compass function";
CM_ SG_ 1892 Day1 "It is the first digit of the day for the date visualization";
CM_ SG_ 1892 Day2 "It is the second digit of the day for the date visualization";
CM_ SG_ 1892 Hour1 "It is the first digit of the hours for the clock visualization";
CM_ SG_ 1892 Hour2 "It is the second digit of the hours for the clock visualization";
CM_ SG_ 1892 Minute1 "It is  the first digit of the minutes for the clock visualization";
CM_ SG_ 1892 Minute2 "It is the second digit of the minutes for the clock visualization";
CM_ SG_ 1892 Month1 "It is the first digit of the month for the date visualization";
CM_ SG_ 1892 Month2 "It is the second digit of the month for the date visualization";
CM_ SG_ 1892 Year1 "It is the first digit of the year for the date visualization";
CM_ SG_ 1892 Year2 "It is the second digit of the year for the date visualization";
CM_ SG_ 1892 Year3 "It is the third digit of the year for the date visualization";
CM_ SG_ 1892 Year4 "It is the fourth digit of the year for the date visualization";
CM_ SG_ 1472 AverageFuelConsumptionAPlus "Used to give information about the average fuel consumption for Trip A.";
CM_ SG_ 1472 AverageSpeedAPlus "Used to give information about the average speed for Trip A.";
CM_ SG_ 1472 PartialOdometerAPlus "Used to give information about the partial odometer for Trip A";
CM_ SG_ 1472 ResetTripAPlusACK "Used to give information about the acknowledge of the reset for Trip A.";
CM_ SG_ 1888 AutonomyDistance "Used to give information about the distance to empty.";
CM_ SG_ 1888 InstantaneousFuelConsumption1 "Used to give information about the tens of the instantaneous fuel consumption value.";
CM_ SG_ 1888 InstantaneousFuelConsumption2 "Used to give information about the units of the instantaneous fuel consumption value.";
CM_ SG_ 1888 InstantaneousFuelConsumption3 "Used to give information about the tenths of the instantaneous fuel consumption value.";
CM_ SG_ 1888 TotalOdometer "Used to give information about the total odometer value in km.";
CM_ SG_ 1476 AverageFuelConsumptionBPlus "Used to give information about the average fuel consumption for Trip B.";
CM_ SG_ 1476 AverageSpeedBPlus "Used to give information about the average speed for Trip B.";
CM_ SG_ 1476 PartialOdometerBPlus "Used to give information about the partial odometer for Trip B.";
CM_ SG_ 1476 ResetTripBPlusACK "Used to give information about the acknowledge of the reset for Trip B.";
CM_ SG_ 748 UConnReq "Requests specific vehicle function";
CM_ SG_ 748 UConnReqAuthCode "Authenticates function requests";
CM_ SG_ 748 UConnReqFOBNum "Indicates Corresponding  FOB number 1-8";
CM_ SG_ 1976 UConnSeed1 "random # for security, Character 1";
CM_ SG_ 1976 UConnSeed2 "random # for security, Character 2";
CM_ SG_ 1976 UConnSeed3 "random # for security, Character 3";
CM_ SG_ 1976 UConnSeed4 "random # for security, Character 4";
CM_ SG_ 1452 DoorChimeBonnetReq "This signal is used to manage the Door Chime for Bonnet";
CM_ SG_ 1452 DoorChimeHatchReq "This signal is used to manage the Door Chime for Hatch";
CM_ SG_ 1452 DoorChimeLFReq "This signal is used to manage the Door Chime for LEFT FRONT
 door";
CM_ SG_ 1452 DoorChimeLRReq "This signal is used to manage the Door Chime for Left Rear door";
CM_ SG_ 1452 DoorChimeRFReq "This signal is used to manage the Door Chime for RIGHT FRONT
 door";
CM_ SG_ 1452 DoorChimeRRReq "This signal is used to manage the Door Chime for Right Rear door";
CM_ SG_ 1452 SBRChimeFrontRowSts "This signal is used to manage the SBR Chime Front Row Status";
CM_ SG_ 1452 SBRChimeRearRowSts "This signal is used to manage the SBR Chime Rear Row Status";
CM_ SG_ 1452 SBRChimeType "This signal is used to manage the SBR Chime Type";
CM_ SG_ 1452 SBRChimeVolume "This signal is used to manage the SBR Chime Volume";
CM_ SG_ 1452 SBRFrontChimeRepetitionRate "This signal is used to manage the SBR Front Chime Repetition Rate";
CM_ SG_ 1452 SBRRearChimeRepetitionRate "This signal is used to manage the SBR Rear Chime Repetition Rate";
CM_ SG_ 992 VIN_DATA "VIN Digits (8 bit ascii encoded)";
CM_ SG_ 992 VIN_MSG "VIN Message Information";

BA_DEF_ SG_ "Accuracy" STRING ;
BA_DEF_ SG_ "Event trans." ENUM "Yes","No";
BA_DEF_ SG_ "GenSigStartValue" INT 0 2147483647;
BA_DEF_ SG_ "GenSigInactiveValue" INT 0 2147483647;
BA_DEF_ SG_ "GenSigSendType" ENUM "NotUsed","OnWrite","OnWriteWithRepetition","OnChange","OnChangeWithRepetition","IfActive","IfActiveWithRepetition","NoSigSendType";
BA_DEF_ BO_ "DiagRequest" ENUM "No","Yes";
BA_DEF_ BO_ "Period [ms]" INT 0 65535;
BA_DEF_ BO_ "Type" ENUM "P","C","PE","COC","PE_Cntrl","E","E_Cntrl","OC","S","BAF","DC","EM","MM","-";
BA_DEF_ BO_ "DiagResponse" ENUM "No","Yes";
BA_DEF_ BO_ "NmMessage" ENUM "No","Yes";
BA_DEF_ BO_ "GenMsgSendType" ENUM "Cyclic","NotUsed","NotUsed","NotUsed","NotUsed","NotUsed","NotUsed","NotUsed","NoMsgSendType";
BA_DEF_ BO_ "GenMsgTimeoutTime" INT 0 10000;
BA_DEF_ BO_ "GenMsgNrOfRepetition" INT 0 255;
BA_DEF_ BO_ "GenMsgILSupport" ENUM "No","Yes";
BA_DEF_ BO_ "GenMsgStartDelayTime" INT 0 65535;
BA_DEF_ BO_ "GenMsgCycleTimeFast" INT 0 65535;
BA_DEF_ BO_ "GenMsgCycleTime" INT 0 65535;
BA_DEF_ BO_ "GenMsgDelayTime" INT 0 65535;
BA_DEF_ BO_ "DiagState" ENUM "No","Yes";
BA_DEF_DEF_ "Accuracy" "";
BA_DEF_DEF_ "Event trans." "No";
BA_DEF_DEF_ "GenSigStartValue" 0;
BA_DEF_DEF_ "GenSigInactiveValue" 0;
BA_DEF_DEF_ "GenSigSendType" "NoSigSendType";
BA_DEF_DEF_ "DiagRequest" "No";
BA_DEF_DEF_ "Period [ms]" 0;
BA_DEF_DEF_ "Type" "-";
BA_DEF_DEF_ "DiagResponse" "No";
BA_DEF_DEF_ "NmMessage" "No";
BA_DEF_DEF_ "GenMsgSendType" "NoMsgSendType";
BA_DEF_DEF_ "GenMsgTimeoutTime" 0;
BA_DEF_DEF_ "GenMsgNrOfRepetition" 0;
BA_DEF_DEF_ "GenMsgILSupport" "No";
BA_DEF_DEF_ "GenMsgStartDelayTime" 0;
BA_DEF_DEF_ "GenMsgCycleTimeFast" 0;
BA_DEF_DEF_ "GenMsgCycleTime" 0;
BA_DEF_DEF_ "GenMsgDelayTime" 0;
BA_DEF_DEF_ "DiagState" "No";
BA_ "Period [ms]" BO_ 2000 1500;
BA_ "Type" BO_ 2000 3;
BA_ "GenMsgSendType" BO_ 2000 0;
BA_ "GenMsgTimeoutTime" BO_ 2000 2500;
BA_ "GenMsgILSupport" BO_ 2000 1;
BA_ "GenMsgStartDelayTime" BO_ 2000 10;
BA_ "GenMsgCycleTime" BO_ 2000 1500;
BA_ "GenMsgDelayTime" BO_ 2000 20;
BA_ "Period [ms]" BO_ 854 250;
BA_ "Type" BO_ 854 3;
BA_ "GenMsgSendType" BO_ 854 0;
BA_ "GenMsgILSupport" BO_ 854 1;
BA_ "GenMsgStartDelayTime" BO_ 854 190;
BA_ "GenMsgCycleTime" BO_ 854 250;
BA_ "GenMsgDelayTime" BO_ 854 20;
BA_ "Period [ms]" BO_ 1132 500;
BA_ "Type" BO_ 1132 3;
BA_ "GenMsgSendType" BO_ 1132 0;
BA_ "GenMsgILSupport" BO_ 1132 1;
BA_ "GenMsgStartDelayTime" BO_ 1132 250;
BA_ "GenMsgCycleTime" BO_ 1132 500;
BA_ "GenMsgDelayTime" BO_ 1132 20;
BA_ "Period [ms]" BO_ 1128 500;
BA_ "Type" BO_ 1128 3;
BA_ "GenMsgSendType" BO_ 1128 0;
BA_ "GenMsgILSupport" BO_ 1128 1;
BA_ "GenMsgStartDelayTime" BO_ 1128 250;
BA_ "GenMsgCycleTime" BO_ 1128 500;
BA_ "GenMsgDelayTime" BO_ 1128 20;
BA_ "Period [ms]" BO_ 988 100;
BA_ "Type" BO_ 988 1;
BA_ "GenMsgSendType" BO_ 988 0;
BA_ "GenMsgTimeoutTime" BO_ 988 2500;
BA_ "GenMsgILSupport" BO_ 988 1;
BA_ "GenMsgStartDelayTime" BO_ 988 10;
BA_ "GenMsgCycleTime" BO_ 988 100;
BA_ "Period [ms]" BO_ 990 100;
BA_ "Type" BO_ 990 1;
BA_ "GenMsgSendType" BO_ 990 0;
BA_ "GenMsgILSupport" BO_ 990 1;
BA_ "GenMsgStartDelayTime" BO_ 990 25;
BA_ "GenMsgCycleTime" BO_ 990 100;
BA_ "Period [ms]" BO_ 994 100;
BA_ "Type" BO_ 994 1;
BA_ "GenMsgSendType" BO_ 994 0;
BA_ "GenMsgTimeoutTime" BO_ 994 2500;
BA_ "GenMsgILSupport" BO_ 994 1;
BA_ "GenMsgStartDelayTime" BO_ 994 60;
BA_ "GenMsgCycleTime" BO_ 994 100;
BA_ "Period [ms]" BO_ 996 100;
BA_ "Type" BO_ 996 1;
BA_ "GenMsgSendType" BO_ 996 0;
BA_ "GenMsgILSupport" BO_ 996 1;
BA_ "GenMsgStartDelayTime" BO_ 996 75;
BA_ "GenMsgCycleTime" BO_ 996 100;
BA_ "Period [ms]" BO_ 998 100;
BA_ "Type" BO_ 998 1;
BA_ "GenMsgSendType" BO_ 998 0;
BA_ "GenMsgILSupport" BO_ 998 1;
BA_ "GenMsgStartDelayTime" BO_ 998 90;
BA_ "GenMsgCycleTime" BO_ 998 100;
BA_ "Period [ms]" BO_ 1984 2000;
BA_ "Type" BO_ 1984 1;
BA_ "GenMsgSendType" BO_ 1984 0;
BA_ "GenMsgILSupport" BO_ 1984 1;
BA_ "GenMsgStartDelayTime" BO_ 1984 1000;
BA_ "GenMsgCycleTime" BO_ 1984 2000;
BA_ "Period [ms]" BO_ 1000 100;
BA_ "Type" BO_ 1000 1;
BA_ "GenMsgSendType" BO_ 1000 0;
BA_ "GenMsgILSupport" BO_ 1000 1;
BA_ "GenMsgCycleTime" BO_ 1000 100;
BA_ "Period [ms]" BO_ 1130 500;
BA_ "Type" BO_ 1130 3;
BA_ "GenMsgSendType" BO_ 1130 0;
BA_ "GenMsgILSupport" BO_ 1130 1;
BA_ "GenMsgCycleTime" BO_ 1130 500;
BA_ "GenMsgDelayTime" BO_ 1130 20;
BA_ "Period [ms]" BO_ 1482 1000;
BA_ "Type" BO_ 1482 3;
BA_ "GenMsgSendType" BO_ 1482 0;
BA_ "GenMsgILSupport" BO_ 1482 1;
BA_ "GenMsgCycleTime" BO_ 1482 1000;
BA_ "GenMsgDelayTime" BO_ 1482 100;
BA_ "Period [ms]" BO_ 1454 1000;
BA_ "Type" BO_ 1454 3;
BA_ "GenMsgSendType" BO_ 1454 0;
BA_ "GenMsgILSupport" BO_ 1454 1;
BA_ "GenMsgCycleTime" BO_ 1454 1000;
BA_ "GenMsgDelayTime" BO_ 1454 100;
BA_ "Period [ms]" BO_ 1448 1000;
BA_ "Type" BO_ 1448 3;
BA_ "GenMsgSendType" BO_ 1448 0;
BA_ "GenMsgILSupport" BO_ 1448 1;
BA_ "GenMsgStartDelayTime" BO_ 1448 20;
BA_ "GenMsgCycleTime" BO_ 1448 1000;
BA_ "GenMsgDelayTime" BO_ 1448 100;
BA_ "Period [ms]" BO_ 1098 500;
BA_ "Type" BO_ 1098 3;
BA_ "GenMsgSendType" BO_ 1098 0;
BA_ "GenMsgTimeoutTime" BO_ 1098 2500;
BA_ "GenMsgILSupport" BO_ 1098 1;
BA_ "GenMsgStartDelayTime" BO_ 1098 250;
BA_ "GenMsgCycleTime" BO_ 1098 500;
BA_ "GenMsgDelayTime" BO_ 1098 20;
BA_ "Period [ms]" BO_ 1462 1000;
BA_ "Type" BO_ 1462 3;
BA_ "GenMsgSendType" BO_ 1462 0;
BA_ "GenMsgILSupport" BO_ 1462 1;
BA_ "GenMsgStartDelayTime" BO_ 1462 165;
BA_ "GenMsgCycleTime" BO_ 1462 1000;
BA_ "GenMsgDelayTime" BO_ 1462 20;
BA_ "Period [ms]" BO_ 1446 1000;
BA_ "Type" BO_ 1446 3;
BA_ "GenMsgSendType" BO_ 1446 0;
BA_ "GenMsgILSupport" BO_ 1446 1;
BA_ "GenMsgStartDelayTime" BO_ 1446 100;
BA_ "GenMsgCycleTime" BO_ 1446 1000;
BA_ "GenMsgDelayTime" BO_ 1446 100;
BA_ "Type" BO_ 1268 11;
BA_ "GenMsgILSupport" BO_ 1268 1;
BA_ "GenMsgDelayTime" BO_ 1268 50;
BA_ "Period [ms]" BO_ 1100 500;
BA_ "Type" BO_ 1100 3;
BA_ "GenMsgSendType" BO_ 1100 0;
BA_ "GenMsgTimeoutTime" BO_ 1100 2500;
BA_ "GenMsgILSupport" BO_ 1100 1;
BA_ "GenMsgStartDelayTime" BO_ 1100 250;
BA_ "GenMsgCycleTime" BO_ 1100 500;
BA_ "GenMsgDelayTime" BO_ 1100 20;
BA_ "Period [ms]" BO_ 1458 1000;
BA_ "Type" BO_ 1458 3;
BA_ "GenMsgSendType" BO_ 1458 0;
BA_ "GenMsgTimeoutTime" BO_ 1458 2500;
BA_ "GenMsgILSupport" BO_ 1458 1;
BA_ "GenMsgStartDelayTime" BO_ 1458 500;
BA_ "GenMsgCycleTime" BO_ 1458 1000;
BA_ "Period [ms]" BO_ 1470 1000;
BA_ "Type" BO_ 1470 3;
BA_ "GenMsgSendType" BO_ 1470 0;
BA_ "GenMsgILSupport" BO_ 1470 1;
BA_ "GenMsgCycleTime" BO_ 1470 1000;
BA_ "GenMsgDelayTime" BO_ 1470 50;
BA_ "Period [ms]" BO_ 1464 250;
BA_ "Type" BO_ 1464 1;
BA_ "GenMsgSendType" BO_ 1464 0;
BA_ "GenMsgTimeoutTime" BO_ 1464 2500;
BA_ "GenMsgILSupport" BO_ 1464 1;
BA_ "GenMsgStartDelayTime" BO_ 1464 120;
BA_ "GenMsgCycleTime" BO_ 1464 250;
BA_ "Type" BO_ 750 7;
BA_ "GenMsgTimeoutTime" BO_ 750 2500;
BA_ "GenMsgILSupport" BO_ 750 1;
BA_ "GenMsgDelayTime" BO_ 750 20;
BA_ "Type" BO_ 144 12;
BA_ "GenMsgILSupport" BO_ 144 1;
BA_ "GenMsgDelayTime" BO_ 144 20;
BA_ "Period [ms]" BO_ 752 100;
BA_ "Type" BO_ 752 1;
BA_ "GenMsgSendType" BO_ 752 0;
BA_ "GenMsgTimeoutTime" BO_ 752 2500;
BA_ "GenMsgILSupport" BO_ 752 1;
BA_ "GenMsgStartDelayTime" BO_ 752 60;
BA_ "GenMsgCycleTime" BO_ 752 100;
BA_ "GenMsgDelayTime" BO_ 752 20;
BA_ "Type" BO_ 136 7;
BA_ "GenMsgILSupport" BO_ 136 1;
BA_ "GenMsgDelayTime" BO_ 136 20;
BA_ "Type" BO_ 156 8;
BA_ "GenMsgILSupport" BO_ 156 1;
BA_ "GenMsgDelayTime" BO_ 156 20;
BA_ "Type" BO_ 158 8;
BA_ "GenMsgILSupport" BO_ 158 1;
BA_ "GenMsgDelayTime" BO_ 158 100;
BA_ "Type" BO_ 162 8;
BA_ "GenMsgILSupport" BO_ 162 1;
BA_ "GenMsgDelayTime" BO_ 162 100;
BA_ "Period [ms]" BO_ 1892 1000;
BA_ "Type" BO_ 1892 1;
BA_ "GenMsgSendType" BO_ 1892 0;
BA_ "GenMsgILSupport" BO_ 1892 1;
BA_ "GenMsgStartDelayTime" BO_ 1892 850;
BA_ "GenMsgCycleTime" BO_ 1892 1000;
BA_ "Period [ms]" BO_ 1472 1000;
BA_ "Type" BO_ 1472 3;
BA_ "GenMsgSendType" BO_ 1472 0;
BA_ "GenMsgILSupport" BO_ 1472 1;
BA_ "GenMsgStartDelayTime" BO_ 1472 150;
BA_ "GenMsgCycleTime" BO_ 1472 1000;
BA_ "GenMsgDelayTime" BO_ 1472 20;
BA_ "Period [ms]" BO_ 1888 1000;
BA_ "Type" BO_ 1888 1;
BA_ "GenMsgSendType" BO_ 1888 0;
BA_ "GenMsgILSupport" BO_ 1888 1;
BA_ "GenMsgStartDelayTime" BO_ 1888 650;
BA_ "GenMsgCycleTime" BO_ 1888 1000;
BA_ "Period [ms]" BO_ 1476 1000;
BA_ "Type" BO_ 1476 3;
BA_ "GenMsgSendType" BO_ 1476 0;
BA_ "GenMsgILSupport" BO_ 1476 1;
BA_ "GenMsgStartDelayTime" BO_ 1476 250;
BA_ "GenMsgCycleTime" BO_ 1476 1000;
BA_ "GenMsgDelayTime" BO_ 1476 20;
BA_ "Type" BO_ 748 9;
BA_ "GenMsgTimeoutTime" BO_ 748 2500;
BA_ "GenMsgNrOfRepetition" BO_ 748 2;
BA_ "GenMsgILSupport" BO_ 748 1;
BA_ "GenMsgCycleTimeFast" BO_ 748 100;
BA_ "GenMsgDelayTime" BO_ 748 20;
BA_ "Type" BO_ 1976 8;
BA_ "GenMsgTimeoutTime" BO_ 1976 2500;
BA_ "GenMsgILSupport" BO_ 1976 1;
BA_ "GenMsgDelayTime" BO_ 1976 20;
BA_ "Period [ms]" BO_ 1452 1000;
BA_ "Type" BO_ 1452 3;
BA_ "GenMsgSendType" BO_ 1452 0;
BA_ "GenMsgILSupport" BO_ 1452 1;
BA_ "GenMsgStartDelayTime" BO_ 1452 40;
BA_ "GenMsgCycleTime" BO_ 1452 1000;
BA_ "GenMsgDelayTime" BO_ 1452 100;
BA_ "Period [ms]" BO_ 992 100;
BA_ "Type" BO_ 992 1;
BA_ "GenMsgSendType" BO_ 992 0;
BA_ "GenMsgILSupport" BO_ 992 1;
BA_ "GenMsgStartDelayTime" BO_ 992 40;
BA_ "GenMsgCycleTime" BO_ 992 100;
BA_ "Event trans." SG_ 2000 AMP_DSS_STATSts 0;
BA_ "GenSigSendType" SG_ 2000 AMP_DSS_STATSts 3;
BA_ "Event trans." SG_ 2000 AMP_MUTEDSts 0;
BA_ "GenSigSendType" SG_ 2000 AMP_MUTEDSts 3;
BA_ "Event trans." SG_ 2000 AUDIOSts_AMP 0;
BA_ "GenSigSendType" SG_ 2000 AUDIOSts_AMP 3;
BA_ "Event trans." SG_ 2000 PowerModeSts_AMP 0;
BA_ "GenSigSendType" SG_ 2000 PowerModeSts_AMP 3;
BA_ "Event trans." SG_ 2000 SURR_AVAILSts 0;
BA_ "GenSigSendType" SG_ 2000 SURR_AVAILSts 3;
BA_ "Accuracy" SG_ 854 BonnetSts "-";
BA_ "Event trans." SG_ 854 BonnetSts 0;
BA_ "GenSigSendType" SG_ 854 BonnetSts 3;
BA_ "Accuracy" SG_ 854 BrakeFluidLevelSts "-";
BA_ "Accuracy" SG_ 854 BrakePadWearSts "-";
BA_ "Event trans." SG_ 854 BrakePadWearSts 0;
BA_ "GenSigSendType" SG_ 854 BrakePadWearSts 3;
BA_ "Accuracy" SG_ 854 DriverDoorSts "-";
BA_ "Event trans." SG_ 854 DriverDoorSts 0;
BA_ "GenSigSendType" SG_ 854 DriverDoorSts 3;
BA_ "Accuracy" SG_ 854 FuelLevel "+/- 2.5 at 17.5%";
BA_ "Accuracy" SG_ 854 FuelLevelFailSts "-";
BA_ "Accuracy" SG_ 854 IMMOCodeWarningLightSts "-";
BA_ "Event trans." SG_ 854 IMMOCodeWarningLightSts 0;
BA_ "GenSigSendType" SG_ 854 IMMOCodeWarningLightSts 3;
BA_ "Accuracy" SG_ 854 LHRDoorSts "-";
BA_ "Event trans." SG_ 854 LHRDoorSts 0;
BA_ "GenSigSendType" SG_ 854 LHRDoorSts 3;
BA_ "Accuracy" SG_ 854 LowFuelWarningSts "-";
BA_ "Event trans." SG_ 854 LowFuelWarningSts 0;
BA_ "GenSigSendType" SG_ 854 LowFuelWarningSts 3;
BA_ "Event trans." SG_ 854 NightAndDaySensorFailSts 0;
BA_ "GenSigSendType" SG_ 854 NightAndDaySensorFailSts 3;
BA_ "Event trans." SG_ 854 OperationalModeSts 0;
BA_ "GenSigSendType" SG_ 854 OperationalModeSts 3;
BA_ "Accuracy" SG_ 854 ParkBrakeSts "-";
BA_ "Event trans." SG_ 854 ParkBrakeSts 0;
BA_ "GenSigSendType" SG_ 854 ParkBrakeSts 3;
BA_ "Accuracy" SG_ 854 PsngrDoorSts "-";
BA_ "Event trans." SG_ 854 PsngrDoorSts 0;
BA_ "GenSigSendType" SG_ 854 PsngrDoorSts 3;
BA_ "Accuracy" SG_ 854 RainSensorFailSts "-";
BA_ "Accuracy" SG_ 854 RearTrunkEnableLastElSts "-";
BA_ "Accuracy" SG_ 854 RHatchSts "-";
BA_ "Event trans." SG_ 854 RHatchSts 0;
BA_ "GenSigSendType" SG_ 854 RHatchSts 3;
BA_ "Accuracy" SG_ 854 RHRDoorSts "-";
BA_ "Event trans." SG_ 854 RHRDoorSts 0;
BA_ "GenSigSendType" SG_ 854 RHRDoorSts 3;
BA_ "Accuracy" SG_ 854 SysEOLSts "-";
BA_ "Accuracy" SG_ 854 WarningKeyInSts "-";
BA_ "Accuracy" SG_ 1132 BatteryChargeSts "5";
BA_ "Accuracy" SG_ 1132 BatteryVoltageLevel "0,05";
BA_ "Event trans." SG_ 1132 CmdIgn_FailSts 0;
BA_ "GenSigSendType" SG_ 1132 CmdIgn_FailSts 3;
BA_ "Event trans." SG_ 1132 CmdIgnSts 0;
BA_ "GenSigSendType" SG_ 1132 CmdIgnSts 3;
BA_ "Accuracy" SG_ 1132 CurrentFailStsIBS "-";
BA_ "Event trans." SG_ 1132 DriveStyleSts 0;
BA_ "GenSigSendType" SG_ 1132 DriveStyleSts 3;
BA_ "GenSigStartValue" SG_ 1132 ExternalTemperatureC 511;
BA_ "GenSigStartValue" SG_ 1132 ExternalTemperatureF 511;
BA_ "Accuracy" SG_ 1132 ExternalTemperatureFailSts "-";
BA_ "Event trans." SG_ 1132 Int_Relay_FailSts 0;
BA_ "GenSigSendType" SG_ 1132 Int_Relay_FailSts 3;
BA_ "Event trans." SG_ 1132 InternalLightLevel 0;
BA_ "GenSigStartValue" SG_ 1132 InternalLightLevel 5;
BA_ "GenSigSendType" SG_ 1132 InternalLightLevel 3;
BA_ "Event trans." SG_ 1132 InternalLightSts 0;
BA_ "GenSigSendType" SG_ 1132 InternalLightSts 3;
BA_ "Event trans." SG_ 1132 RemStActvSts 0;
BA_ "GenSigSendType" SG_ 1132 RemStActvSts 3;
BA_ "Event trans." SG_ 1132 TurnIndicationSts 0;
BA_ "GenSigSendType" SG_ 1132 TurnIndicationSts 3;
BA_ "Event trans." SG_ 1128 ClusterLightSts 0;
BA_ "GenSigSendType" SG_ 1128 ClusterLightSts 3;
BA_ "Event trans." SG_ 1128 E_CALL_PSD 0;
BA_ "GenSigSendType" SG_ 1128 E_CALL_PSD 3;
BA_ "Event trans." SG_ 1128 U_CALL_PSD 0;
BA_ "GenSigSendType" SG_ 1128 U_CALL_PSD 3;
BA_ "Accuracy" SG_ 988 LatAcceleration_BSM "-";
BA_ "Accuracy" SG_ 988 LatAccelerationFailSts_BSM "-";
BA_ "Accuracy" SG_ 988 LongAcceleration_BSM "-";
BA_ "Accuracy" SG_ 988 LongAccelerationFailSts_BSM "-";
BA_ "Accuracy" SG_ 988 Slope "-";
BA_ "Accuracy" SG_ 988 YawRate_BSM "-";
BA_ "Accuracy" SG_ 988 YawRateFailSts_BSM "-";
BA_ "Accuracy" SG_ 990 LHF_FastPulseCounter "-";
BA_ "Accuracy" SG_ 990 LHF_WheelSensorFailSts "-";
BA_ "Accuracy" SG_ 990 LHR_FastPulseCounter "-";
BA_ "Accuracy" SG_ 990 LHR_WheelSensorFailSts "-";
BA_ "Accuracy" SG_ 990 RHF_FastPulseCounter "-";
BA_ "Accuracy" SG_ 990 RHF_WheelSensorFailSts "-";
BA_ "Accuracy" SG_ 990 RHR_FastPulseCounter "-";
BA_ "Accuracy" SG_ 990 RHR_WheelSensorFailSts "-";
BA_ "GenSigStartValue" SG_ 994 ACPressure 511;
BA_ "GenSigStartValue" SG_ 994 AlternatorFail 1;
BA_ "GenSigStartValue" SG_ 994 CompressorSts 2;
BA_ "GenSigStartValue" SG_ 994 EngineSts 3;
BA_ "Accuracy" SG_ 994 EngineWaterTemp "-";
BA_ "Accuracy" SG_ 994 EngineWaterTempFailSts "-";
BA_ "GenSigStartValue" SG_ 994 ESS_ENG_ST 15;
BA_ "Accuracy" SG_ 996 DPFSts "-";
BA_ "Accuracy" SG_ 996 FuelConsumption_GAG "-";
BA_ "Accuracy" SG_ 996 GearShiftIndication "-";
BA_ "GenSigStartValue" SG_ 998 EngineTorque 2047;
BA_ "Accuracy" SG_ 1984 InflationState_LHF_Tyre "-";
BA_ "Accuracy" SG_ 1984 InflationState_LHR_Tyre "-";
BA_ "Accuracy" SG_ 1984 InflationState_RHF_Tyre "-";
BA_ "Accuracy" SG_ 1984 InflationState_RHR_Tyre "-";
BA_ "Accuracy" SG_ 1984 PressureValue_LHF_Tyre "+/- 0,1 bar";
BA_ "Accuracy" SG_ 1984 PressureValue_LHR_Tyre "+/- 0,1 bar";
BA_ "Accuracy" SG_ 1984 PressureValue_RHF_Tyre "+/- 0,1 bar";
BA_ "Accuracy" SG_ 1984 PressureValue_RHR_Tyre "+/- 0,1 bar";
BA_ "Accuracy" SG_ 1984 TyrePressureSystemFailSts "-";
BA_ "Accuracy" SG_ 1000 EngineOilLevel "-";
BA_ "Accuracy" SG_ 1000 ThrottlePosition "+/- 0,392";
BA_ "GenSigStartValue" SG_ 1130 A2D_DRV_TEMP_DR_POS 819;
BA_ "GenSigStartValue" SG_ 1130 A2D_FT_HVAC_BLOWER_VOLTAGE 479;
BA_ "Accuracy" SG_ 1130 AcOutputCurrentSts "-";
BA_ "Accuracy" SG_ 1130 CompressorACReqSts "-";
BA_ "Event trans." SG_ 1130 CompressorACReqSts 0;
BA_ "GenSigSendType" SG_ 1130 CompressorACReqSts 3;
BA_ "Event trans." SG_ 1130 HVAC_SAM_enable 0;
BA_ "GenSigSendType" SG_ 1130 HVAC_SAM_enable 3;
BA_ "Accuracy" SG_ 1130 MaxDefrostSts "-";
BA_ "Event trans." SG_ 1130 MaxDefrostSts 0;
BA_ "GenSigSendType" SG_ 1130 MaxDefrostSts 3;
BA_ "Accuracy" SG_ 1130 PowerModeSts_Climate "-";
BA_ "Event trans." SG_ 1130 PowerModeSts_Climate 0;
BA_ "GenSigSendType" SG_ 1130 PowerModeSts_Climate 3;
BA_ "Accuracy" SG_ 1130 PTCFailSts "-";
BA_ "Event trans." SG_ 1130 PTCFailSts 0;
BA_ "GenSigSendType" SG_ 1130 PTCFailSts 3;
BA_ "Accuracy" SG_ 1130 PTCSts "-";
BA_ "Event trans." SG_ 1130 PTCSts 0;
BA_ "GenSigSendType" SG_ 1130 PTCSts 3;
BA_ "Accuracy" SG_ 1130 RHeatedWindowCmd "-";
BA_ "Event trans." SG_ 1130 RHeatedWindowCmd 0;
BA_ "GenSigSendType" SG_ 1130 RHeatedWindowCmd 3;
BA_ "Accuracy" SG_ 1130 StopStartClimateInfo "-";
BA_ "Event trans." SG_ 1130 StopStartClimateInfo 0;
BA_ "GenSigSendType" SG_ 1130 StopStartClimateInfo 3;
BA_ "Accuracy" SG_ 1130 StopStartEnable "-";
BA_ "Event trans." SG_ 1130 StopStartEnable 0;
BA_ "GenSigStartValue" SG_ 1130 StopStartEnable 1;
BA_ "GenSigSendType" SG_ 1130 StopStartEnable 3;
BA_ "Event trans." SG_ 1482 BlowerDisplay 0;
BA_ "GenSigSendType" SG_ 1482 BlowerDisplay 3;
BA_ "Event trans." SG_ 1482 DegreeUnit 0;
BA_ "GenSigSendType" SG_ 1482 DegreeUnit 3;
BA_ "Event trans." SG_ 1482 HeatedLeft 0;
BA_ "GenSigSendType" SG_ 1482 HeatedLeft 3;
BA_ "Event trans." SG_ 1482 HeatedRight 0;
BA_ "GenSigSendType" SG_ 1482 HeatedRight 3;
BA_ "Event trans." SG_ 1482 ModeDefrostLeft 0;
BA_ "GenSigSendType" SG_ 1482 ModeDefrostLeft 3;
BA_ "Event trans." SG_ 1482 ModeDefrostRight 0;
BA_ "GenSigSendType" SG_ 1482 ModeDefrostRight 3;
BA_ "Event trans." SG_ 1482 ModeFloorLeft 0;
BA_ "GenSigSendType" SG_ 1482 ModeFloorLeft 3;
BA_ "Event trans." SG_ 1482 ModeFloorRight 0;
BA_ "GenSigSendType" SG_ 1482 ModeFloorRight 3;
BA_ "Event trans." SG_ 1482 ModeVentLeft 0;
BA_ "GenSigSendType" SG_ 1482 ModeVentLeft 3;
BA_ "Event trans." SG_ 1482 ModeVentRight 0;
BA_ "GenSigSendType" SG_ 1482 ModeVentRight 3;
BA_ "Event trans." SG_ 1482 OFFSts 0;
BA_ "GenSigSendType" SG_ 1482 OFFSts 3;
BA_ "Event trans." SG_ 1482 ShowHVACPopup 0;
BA_ "GenSigSendType" SG_ 1482 ShowHVACPopup 3;
BA_ "Event trans." SG_ 1482 SteeringHeatedCmd 0;
BA_ "GenSigSendType" SG_ 1482 SteeringHeatedCmd 3;
BA_ "Event trans." SG_ 1482 TempLeftDisplay 0;
BA_ "GenSigSendType" SG_ 1482 TempLeftDisplay 3;
BA_ "Event trans." SG_ 1482 TempRightDisplay 0;
BA_ "GenSigSendType" SG_ 1482 TempRightDisplay 3;
BA_ "Event trans." SG_ 1482 VentilatedLeft 0;
BA_ "GenSigSendType" SG_ 1482 VentilatedLeft 3;
BA_ "Event trans." SG_ 1482 VentilatedRight 0;
BA_ "GenSigSendType" SG_ 1482 VentilatedRight 3;
BA_ "Event trans." SG_ 1482 WordingLeftDisplay 0;
BA_ "GenSigSendType" SG_ 1482 WordingLeftDisplay 3;
BA_ "Event trans." SG_ 1482 WordingRightDisplay 0;
BA_ "GenSigSendType" SG_ 1482 WordingRightDisplay 3;
BA_ "Accuracy" SG_ 1454 AUDIOSts_ESEM "-";
BA_ "Event trans." SG_ 1454 AUDIOSts_ESEM 0;
BA_ "GenSigSendType" SG_ 1454 AUDIOSts_ESEM 3;
BA_ "Accuracy" SG_ 1454 PowerModeSts_ESEM "-";
BA_ "Event trans." SG_ 1454 PowerModeSts_ESEM 0;
BA_ "GenSigSendType" SG_ 1454 PowerModeSts_ESEM 3;
BA_ "Accuracy" SG_ 1448 Ack_beep "-";
BA_ "Accuracy" SG_ 1448 DataCmdReady "-";
BA_ "Event trans." SG_ 1448 DataCmdReady 0;
BA_ "GenSigSendType" SG_ 1448 DataCmdReady 3;
BA_ "Accuracy" SG_ 1448 MirrorPsngrVerticalPosCmd "-";
BA_ "Event trans." SG_ 1098 BSS_LF_Chime_RQSts 0;
BA_ "GenSigSendType" SG_ 1098 BSS_LF_Chime_RQSts 3;
BA_ "Event trans." SG_ 1098 BSS_LR_Chime_RQSts 0;
BA_ "GenSigSendType" SG_ 1098 BSS_LR_Chime_RQSts 3;
BA_ "Event trans." SG_ 1098 BSS_LT_Blind_RQSts 0;
BA_ "GenSigSendType" SG_ 1098 BSS_LT_Blind_RQSts 3;
BA_ "Event trans." SG_ 1098 BSS_LT_CFG_STATSts 0;
BA_ "GenSigSendType" SG_ 1098 BSS_LT_CFG_STATSts 3;
BA_ "Event trans." SG_ 1098 BSS_LT_Chime_TypeSts 0;
BA_ "GenSigSendType" SG_ 1098 BSS_LT_Chime_TypeSts 3;
BA_ "Event trans." SG_ 1098 BSS_LT_OPR_StatSts 0;
BA_ "GenSigSendType" SG_ 1098 BSS_LT_OPR_StatSts 3;
BA_ "Event trans." SG_ 1098 BSS_LT_SRV_RQSts 0;
BA_ "GenSigSendType" SG_ 1098 BSS_LT_SRV_RQSts 3;
BA_ "Event trans." SG_ 1098 BssLtLedFaultSts 0;
BA_ "GenSigSendType" SG_ 1098 BssLtLedFaultSts 3;
BA_ "Event trans." SG_ 1098 BssLtWrnSts 0;
BA_ "GenSigSendType" SG_ 1098 BssLtWrnSts 3;
BA_ "Event trans." SG_ 1462 DynamicGridFailSts 0;
BA_ "GenSigSendType" SG_ 1462 DynamicGridFailSts 3;
BA_ "Event trans." SG_ 1462 DynamicGridSts 0;
BA_ "GenSigStartValue" SG_ 1462 DynamicGridSts 1;
BA_ "GenSigSendType" SG_ 1462 DynamicGridSts 3;
BA_ "Event trans." SG_ 1462 StW_TempSensSts 0;
BA_ "GenSigSendType" SG_ 1462 StW_TempSensSts 3;
BA_ "Event trans." SG_ 1462 SWSError 0;
BA_ "GenSigSendType" SG_ 1462 SWSError 3;
BA_ "Event trans." SG_ 1446 MirrorDrvStandStillSts 0;
BA_ "GenSigSendType" SG_ 1446 MirrorDrvStandStillSts 3;
BA_ "Accuracy" SG_ 1446 MirrorPsngrHorizzontalPosSts "-";
BA_ "Accuracy" SG_ 1446 MirrorPsngrStandStillSts "-";
BA_ "Event trans." SG_ 1446 MirrorPsngrStandStillSts 0;
BA_ "GenSigSendType" SG_ 1446 MirrorPsngrStandStillSts 3;
BA_ "Accuracy" SG_ 1446 MirrorPsngrVerticalPosSts "-";
BA_ "Accuracy" SG_ 1268 PAMSystemFault "-";
BA_ "Event trans." SG_ 1100 BSS_RF_Chime_RQSts 0;
BA_ "GenSigSendType" SG_ 1100 BSS_RF_Chime_RQSts 3;
BA_ "Event trans." SG_ 1100 BSS_RR_Chime_RQSts 0;
BA_ "GenSigSendType" SG_ 1100 BSS_RR_Chime_RQSts 3;
BA_ "Event trans." SG_ 1100 BSS_RT_Blind_RQSts 0;
BA_ "GenSigSendType" SG_ 1100 BSS_RT_Blind_RQSts 3;
BA_ "Event trans." SG_ 1100 BSS_RT_CFG_STATSts 0;
BA_ "GenSigSendType" SG_ 1100 BSS_RT_CFG_STATSts 3;
BA_ "Event trans." SG_ 1100 BSS_RT_Chime_TypeSts 0;
BA_ "GenSigSendType" SG_ 1100 BSS_RT_Chime_TypeSts 3;
BA_ "Event trans." SG_ 1100 BSS_RT_OPR_StatSts 0;
BA_ "GenSigSendType" SG_ 1100 BSS_RT_OPR_StatSts 3;
BA_ "Event trans." SG_ 1100 BSS_RT_SRV_RQSts 0;
BA_ "GenSigSendType" SG_ 1100 BSS_RT_SRV_RQSts 3;
BA_ "Event trans." SG_ 1100 BssRtLedFaultSts 0;
BA_ "GenSigSendType" SG_ 1100 BssRtLedFaultSts 3;
BA_ "Event trans." SG_ 1100 BssRtWrnSts 0;
BA_ "GenSigSendType" SG_ 1100 BssRtWrnSts 3;
BA_ "Event trans." SG_ 1458 ConnectivityStatus 0;
BA_ "GenSigSendType" SG_ 1458 ConnectivityStatus 3;
BA_ "Event trans." SG_ 1458 PowerModeSts_TBM 0;
BA_ "GenSigSendType" SG_ 1458 PowerModeSts_TBM 3;
BA_ "Event trans." SG_ 1458 RemoteUpdateStatus 0;
BA_ "GenSigSendType" SG_ 1458 RemoteUpdateStatus 3;
BA_ "Event trans." SG_ 1458 SOSCallStatus 0;
BA_ "GenSigSendType" SG_ 1458 SOSCallStatus 3;
BA_ "Event trans." SG_ 1458 SOSCallType 0;
BA_ "GenSigSendType" SG_ 1458 SOSCallType 3;
BA_ "Accuracy" SG_ 1470 AntitheftSts "-";
BA_ "Event trans." SG_ 1470 AntitheftSts 0;
BA_ "GenSigSendType" SG_ 1470 AntitheftSts 3;
BA_ "Accuracy" SG_ 1470 AUDIOSts_Telematic "-";
BA_ "Event trans." SG_ 1470 AUDIOSts_Telematic 0;
BA_ "GenSigSendType" SG_ 1470 AUDIOSts_Telematic 3;
BA_ "Accuracy" SG_ 1470 CurrentSource "-";
BA_ "Event trans." SG_ 1470 CurrentSource 0;
BA_ "GenSigSendType" SG_ 1470 CurrentSource 3;
BA_ "Accuracy" SG_ 1470 E_CALL_STAT "-";
BA_ "Event trans." SG_ 1470 E_CALL_STAT 0;
BA_ "GenSigSendType" SG_ 1470 E_CALL_STAT 3;
BA_ "Accuracy" SG_ 1470 HFPSts "-";
BA_ "Event trans." SG_ 1470 HFPSts 0;
BA_ "GenSigSendType" SG_ 1470 HFPSts 3;
BA_ "Accuracy" SG_ 1470 MuteSts "-";
BA_ "Event trans." SG_ 1470 MuteSts 0;
BA_ "GenSigSendType" SG_ 1470 MuteSts 3;
BA_ "Accuracy" SG_ 1470 Popup_Feedback "-";
BA_ "Event trans." SG_ 1470 Popup_Feedback 0;
BA_ "GenSigSendType" SG_ 1470 Popup_Feedback 3;
BA_ "Accuracy" SG_ 1470 PowerModeSts_Telematic "-";
BA_ "Event trans." SG_ 1470 PowerModeSts_Telematic 0;
BA_ "GenSigSendType" SG_ 1470 PowerModeSts_Telematic 3;
BA_ "Accuracy" SG_ 1470 PowerSts_Telematic "-";
BA_ "Event trans." SG_ 1470 PowerSts_Telematic 0;
BA_ "GenSigSendType" SG_ 1470 PowerSts_Telematic 3;
BA_ "Accuracy" SG_ 1470 U_CALL_STAT "-";
BA_ "Event trans." SG_ 1470 U_CALL_STAT 0;
BA_ "GenSigSendType" SG_ 1470 U_CALL_STAT 3;
BA_ "Accuracy" SG_ 1470 VRSts "-";
BA_ "Event trans." SG_ 1470 VRSts 0;
BA_ "GenSigSendType" SG_ 1470 VRSts 3;
BA_ "Event trans." SG_ 750 Command_01Sts 0;
BA_ "GenSigSendType" SG_ 750 Command_01Sts 3;
BA_ "Event trans." SG_ 750 Command_02Sts 0;
BA_ "GenSigSendType" SG_ 750 Command_02Sts 3;
BA_ "Event trans." SG_ 750 Command_03Sts 0;
BA_ "GenSigSendType" SG_ 750 Command_03Sts 3;
BA_ "Event trans." SG_ 750 Command_04Sts 0;
BA_ "GenSigSendType" SG_ 750 Command_04Sts 3;
BA_ "Event trans." SG_ 750 Command_05Sts 0;
BA_ "GenSigSendType" SG_ 750 Command_05Sts 3;
BA_ "Event trans." SG_ 750 Knob_Encoder_CMD_Dir 0;
BA_ "GenSigSendType" SG_ 750 Knob_Encoder_CMD_Dir 3;
BA_ "Event trans." SG_ 750 Knob_Encoder_CMD_Val 0;
BA_ "GenSigStartValue" SG_ 750 Knob_Encoder_CMD_Val 127;
BA_ "GenSigSendType" SG_ 750 Knob_Encoder_CMD_Val 3;
BA_ "Accuracy" SG_ 144 FrameNumber "-";
BA_ "Event trans." SG_ 144 FrameNumber 0;
BA_ "GenSigSendType" SG_ 144 FrameNumber 1;
BA_ "Accuracy" SG_ 144 InfoCode "-";
BA_ "Accuracy" SG_ 144 TotalFrameNumber "-";
BA_ "Accuracy" SG_ 144 UTF_Text_1 "-";
BA_ "Accuracy" SG_ 144 UTF_Text_2 "-";
BA_ "Accuracy" SG_ 144 UTF_Text_3 "-";
BA_ "Accuracy" SG_ 752 AccelerationIndex "-";
BA_ "Event trans." SG_ 752 AccelerationIndex 0;
BA_ "Accuracy" SG_ 752 DecelerationIndex "-";
BA_ "Event trans." SG_ 752 DecelerationIndex 0;
BA_ "Accuracy" SG_ 752 FuelTargetMAX "-";
BA_ "Event trans." SG_ 752 FuelTargetMAX 0;
BA_ "Accuracy" SG_ 752 FuelTargetMIN "-";
BA_ "Event trans." SG_ 752 FuelTargetMIN 0;
BA_ "Accuracy" SG_ 752 GearIndex "-";
BA_ "Event trans." SG_ 752 GearIndex 0;
BA_ "Accuracy" SG_ 752 GeneralEcoIndex "-";
BA_ "Event trans." SG_ 752 GeneralEcoIndex 0;
BA_ "Accuracy" SG_ 752 SpeedIndex "-";
BA_ "Event trans." SG_ 752 SpeedIndex 0;
BA_ "Accuracy" SG_ 136 Direction "-";
BA_ "Event trans." SG_ 136 Direction 0;
BA_ "GenSigSendType" SG_ 136 Direction 3;
BA_ "Accuracy" SG_ 136 DistToTurn "-";
BA_ "Event trans." SG_ 136 DistToTurn 0;
BA_ "GenSigSendType" SG_ 136 DistToTurn 3;
BA_ "Accuracy" SG_ 136 LastAnnouncement "-";
BA_ "Event trans." SG_ 136 LastAnnouncement 0;
BA_ "GenSigSendType" SG_ 136 LastAnnouncement 3;
BA_ "Accuracy" SG_ 136 ResolutionDistToTurn "-";
BA_ "Accuracy" SG_ 136 Unit "-";
BA_ "Event trans." SG_ 136 Unit 0;
BA_ "GenSigStartValue" SG_ 136 Unit 6;
BA_ "GenSigSendType" SG_ 136 Unit 3;
BA_ "Accuracy" SG_ 156 Day1_TLM "-";
BA_ "Event trans." SG_ 156 Day1_TLM 0;
BA_ "GenSigSendType" SG_ 156 Day1_TLM 1;
BA_ "Accuracy" SG_ 156 Day2_TLM "-";
BA_ "Accuracy" SG_ 156 Hour1_TLM "-";
BA_ "Accuracy" SG_ 156 Hour2_TLM "-";
BA_ "Accuracy" SG_ 156 Minute1_TLM "-";
BA_ "Accuracy" SG_ 156 Minute2_TLM "-";
BA_ "Accuracy" SG_ 156 Month1_TLM "-";
BA_ "Accuracy" SG_ 156 Month2_TLM "-";
BA_ "Accuracy" SG_ 156 Year1_TLM "-";
BA_ "Accuracy" SG_ 156 Year2_TLM "-";
BA_ "Accuracy" SG_ 156 Year3_TLM "-";
BA_ "Accuracy" SG_ 156 Year4_TLM "-";
BA_ "Event trans." SG_ 158 AmbientLightingLevel_Req 0;
BA_ "GenSigStartValue" SG_ 158 AmbientLightingLevel_Req 4;
BA_ "GenSigSendType" SG_ 158 AmbientLightingLevel_Req 1;
BA_ "Event trans." SG_ 158 AudioRepetition_Req 0;
BA_ "GenSigSendType" SG_ 158 AudioRepetition_Req 1;
BA_ "Accuracy" SG_ 158 AutoHighBeamEnable_Req "-";
BA_ "Event trans." SG_ 158 AutoHighBeamEnable_Req 0;
BA_ "GenSigStartValue" SG_ 158 AutoHighBeamEnable_Req 1;
BA_ "GenSigSendType" SG_ 158 AutoHighBeamEnable_Req 1;
BA_ "Event trans." SG_ 158 AutomaticResetTripB_Req 0;
BA_ "GenSigSendType" SG_ 158 AutomaticResetTripB_Req 1;
BA_ "Event trans." SG_ 158 AutoParkBrake_Req 0;
BA_ "GenSigSendType" SG_ 158 AutoParkBrake_Req 1;
BA_ "Event trans." SG_ 158 AutoRelock_Req 0;
BA_ "GenSigSendType" SG_ 158 AutoRelock_Req 1;
BA_ "Accuracy" SG_ 158 BSDEnable_Req "-";
BA_ "Event trans." SG_ 158 BSDEnable_Req 0;
BA_ "GenSigStartValue" SG_ 158 BSDEnable_Req 2;
BA_ "GenSigSendType" SG_ 158 BSDEnable_Req 1;
BA_ "Accuracy" SG_ 158 ConsumptionUnit_Req "-";
BA_ "Event trans." SG_ 158 ConsumptionUnit_Req 0;
BA_ "GenSigSendType" SG_ 158 ConsumptionUnit_Req 1;
BA_ "Accuracy" SG_ 158 CorneringEnable_Req "-";
BA_ "Event trans." SG_ 158 CorneringEnable_Req 0;
BA_ "GenSigSendType" SG_ 158 CorneringEnable_Req 1;
BA_ "Accuracy" SG_ 158 DistanceUnit_Req "-";
BA_ "Event trans." SG_ 158 DistanceUnit_Req 0;
BA_ "GenSigSendType" SG_ 158 DistanceUnit_Req 1;
BA_ "Accuracy" SG_ 158 DRLEnable_Req "-";
BA_ "Event trans." SG_ 158 DRLEnable_Req 0;
BA_ "GenSigSendType" SG_ 158 DRLEnable_Req 1;
BA_ "Event trans." SG_ 158 DynamicGrid_Req 0;
BA_ "GenSigStartValue" SG_ 158 DynamicGrid_Req 1;
BA_ "GenSigSendType" SG_ 158 DynamicGrid_Req 1;
BA_ "Accuracy" SG_ 158 ExternalLightSensorLevel_Req "-";
BA_ "Event trans." SG_ 158 ExternalLightSensorLevel_Req 0;
BA_ "GenSigStartValue" SG_ 158 ExternalLightSensorLevel_Req 1;
BA_ "GenSigSendType" SG_ 158 ExternalLightSensorLevel_Req 1;
BA_ "Accuracy" SG_ 158 GreetingLightsEnable_Req "-";
BA_ "Event trans." SG_ 158 GreetingLightsEnable_Req 0;
BA_ "GenSigSendType" SG_ 158 GreetingLightsEnable_Req 1;
BA_ "Accuracy" SG_ 158 HourMode_Req "-";
BA_ "Event trans." SG_ 158 HourMode_Req 0;
BA_ "GenSigSendType" SG_ 158 HourMode_Req 1;
BA_ "Accuracy" SG_ 158 LanguageSelection_Req "-";
BA_ "Event trans." SG_ 158 LanguageSelection_Req 0;
BA_ "GenSigSendType" SG_ 158 LanguageSelection_Req 1;
BA_ "Event trans." SG_ 158 NavigationRepetition_Req 0;
BA_ "GenSigSendType" SG_ 158 NavigationRepetition_Req 1;
BA_ "Event trans." SG_ 158 PamAlertMode_Req 0;
BA_ "GenSigStartValue" SG_ 158 PamAlertMode_Req 2;
BA_ "GenSigSendType" SG_ 158 PamAlertMode_Req 1;
BA_ "Event trans." SG_ 158 PamChimeVolumeFront_Req 0;
BA_ "GenSigStartValue" SG_ 158 PamChimeVolumeFront_Req 1;
BA_ "GenSigSendType" SG_ 158 PamChimeVolumeFront_Req 1;
BA_ "Event trans." SG_ 158 PamChimeVolumeRear_Req 0;
BA_ "GenSigStartValue" SG_ 158 PamChimeVolumeRear_Req 1;
BA_ "GenSigSendType" SG_ 158 PamChimeVolumeRear_Req 1;
BA_ "Event trans." SG_ 158 PassiveEntry_Req 0;
BA_ "GenSigSendType" SG_ 158 PassiveEntry_Req 1;
BA_ "Event trans." SG_ 158 PhoneRepetition_Req 0;
BA_ "GenSigSendType" SG_ 158 PhoneRepetition_Req 1;
BA_ "Event trans." SG_ 158 RemoteDoorUnlock_Req 0;
BA_ "GenSigStartValue" SG_ 158 RemoteDoorUnlock_Req 1;
BA_ "GenSigSendType" SG_ 158 RemoteDoorUnlock_Req 1;
BA_ "Accuracy" SG_ 158 ResetTripA_Req "-";
BA_ "Event trans." SG_ 158 ResetTripA_Req 0;
BA_ "GenSigSendType" SG_ 158 ResetTripA_Req 1;
BA_ "Accuracy" SG_ 158 ResetTripB_Req "-";
BA_ "Event trans." SG_ 158 ResetTripB_Req 0;
BA_ "GenSigSendType" SG_ 158 ResetTripB_Req 1;
BA_ "Event trans." SG_ 158 SoundHornLock_Req 0;
BA_ "GenSigStartValue" SG_ 158 SoundHornLock_Req 1;
BA_ "GenSigSendType" SG_ 158 SoundHornLock_Req 1;
BA_ "Event trans." SG_ 158 SoundHornRemoteStart_Req 0;
BA_ "GenSigSendType" SG_ 158 SoundHornRemoteStart_Req 1;
BA_ "Accuracy" SG_ 158 SpeedLockDoorEnable_Req "-";
BA_ "Event trans." SG_ 158 SpeedLockDoorEnable_Req 0;
BA_ "GenSigSendType" SG_ 158 SpeedLockDoorEnable_Req 1;
BA_ "Accuracy" SG_ 158 TemperatureUnit_Req "-";
BA_ "Event trans." SG_ 158 TemperatureUnit_Req 0;
BA_ "GenSigSendType" SG_ 158 TemperatureUnit_Req 1;
BA_ "Accuracy" SG_ 158 Trip_B_Enable_Req "-";
BA_ "Event trans." SG_ 158 Trip_B_Enable_Req 0;
BA_ "GenSigStartValue" SG_ 158 Trip_B_Enable_Req 1;
BA_ "GenSigSendType" SG_ 158 Trip_B_Enable_Req 1;
BA_ "Accuracy" SG_ 162 AutoUnlockDoorExit_Req "-";
BA_ "Event trans." SG_ 162 AutoUnlockDoorExit_Req 0;
BA_ "GenSigStartValue" SG_ 162 AutoUnlockDoorExit_Req 1;
BA_ "GenSigSendType" SG_ 162 AutoUnlockDoorExit_Req 1;
BA_ "Accuracy" SG_ 162 BrakeService_Req "-";
BA_ "Event trans." SG_ 162 BrakeService_Req 0;
BA_ "GenSigSendType" SG_ 162 BrakeService_Req 1;
BA_ "Accuracy" SG_ 162 BuzzerVolume_Req "-";
BA_ "Event trans." SG_ 162 BuzzerVolume_Req 0;
BA_ "GenSigSendType" SG_ 162 BuzzerVolume_Req 1;
BA_ "Accuracy" SG_ 162 CalibrationSetup_Req "-";
BA_ "Event trans." SG_ 162 CalibrationSetup_Req 0;
BA_ "GenSigSendType" SG_ 162 CalibrationSetup_Req 1;
BA_ "Accuracy" SG_ 162 EPB_MaintenanceMode_Req "-";
BA_ "Event trans." SG_ 162 EPB_MaintenanceMode_Req 0;
BA_ "GenSigSendType" SG_ 162 EPB_MaintenanceMode_Req 1;
BA_ "Accuracy" SG_ 162 FlashLightWLock_Req "-";
BA_ "Event trans." SG_ 162 FlashLightWLock_Req 0;
BA_ "GenSigStartValue" SG_ 162 FlashLightWLock_Req 1;
BA_ "GenSigSendType" SG_ 162 FlashLightWLock_Req 1;
BA_ "Accuracy" SG_ 162 FrontPassengerAirBag_Req "-";
BA_ "Event trans." SG_ 162 FrontPassengerAirBag_Req 0;
BA_ "GenSigSendType" SG_ 162 FrontPassengerAirBag_Req 1;
BA_ "Accuracy" SG_ 162 FSFCWPlusActivationMode_Req "-";
BA_ "Event trans." SG_ 162 FSFCWPlusActivationMode_Req 0;
BA_ "GenSigStartValue" SG_ 162 FSFCWPlusActivationMode_Req 1;
BA_ "GenSigSendType" SG_ 162 FSFCWPlusActivationMode_Req 1;
BA_ "Accuracy" SG_ 162 FSFCWPlusSetting_Req "-";
BA_ "Event trans." SG_ 162 FSFCWPlusSetting_Req 0;
BA_ "GenSigStartValue" SG_ 162 FSFCWPlusSetting_Req 3;
BA_ "GenSigSendType" SG_ 162 FSFCWPlusSetting_Req 1;
BA_ "Accuracy" SG_ 162 HeadlightsOffDelay_Req "-";
BA_ "Event trans." SG_ 162 HeadlightsOffDelay_Req 0;
BA_ "GenSigSendType" SG_ 162 HeadlightsOffDelay_Req 1;
BA_ "Accuracy" SG_ 162 HHDisabling_Req "-";
BA_ "Event trans." SG_ 162 HHDisabling_Req 0;
BA_ "GenSigSendType" SG_ 162 HHDisabling_Req 1;
BA_ "Accuracy" SG_ 162 LDW_Sensibility_Req "-";
BA_ "Event trans." SG_ 162 LDW_Sensibility_Req 0;
BA_ "GenSigStartValue" SG_ 162 LDW_Sensibility_Req 3;
BA_ "GenSigSendType" SG_ 162 LDW_Sensibility_Req 1;
BA_ "Accuracy" SG_ 162 SeatBeltReminder_Req "-";
BA_ "Event trans." SG_ 162 SeatBeltReminder_Req 0;
BA_ "GenSigSendType" SG_ 162 SeatBeltReminder_Req 1;
BA_ "Accuracy" SG_ 162 SpeedLimitSet_Req "-";
BA_ "Event trans." SG_ 162 SpeedLimitSet_Req 0;
BA_ "GenSigSendType" SG_ 162 SpeedLimitSet_Req 1;
BA_ "Accuracy" SG_ 162 SpeedLimitSts_Req "-";
BA_ "Event trans." SG_ 162 SpeedLimitSts_Req 0;
BA_ "GenSigSendType" SG_ 162 SpeedLimitSts_Req 1;
BA_ "Accuracy" SG_ 162 TyrePressureUnit_Req "-";
BA_ "Event trans." SG_ 162 TyrePressureUnit_Req 0;
BA_ "GenSigStartValue" SG_ 162 TyrePressureUnit_Req 2;
BA_ "GenSigSendType" SG_ 162 TyrePressureUnit_Req 1;
BA_ "Accuracy" SG_ 162 Units_Req "-";
BA_ "Event trans." SG_ 162 Units_Req 0;
BA_ "GenSigStartValue" SG_ 162 Units_Req 2;
BA_ "GenSigSendType" SG_ 162 Units_Req 1;
BA_ "Accuracy" SG_ 162 VarianceSet_Req "-";
BA_ "Event trans." SG_ 162 VarianceSet_Req 0;
BA_ "GenSigSendType" SG_ 162 VarianceSet_Req 1;
BA_ "Accuracy" SG_ 1892 Day1 "-";
BA_ "Accuracy" SG_ 1892 Day2 "-";
BA_ "Accuracy" SG_ 1892 Hour1 "-";
BA_ "Accuracy" SG_ 1892 Hour2 "-";
BA_ "Accuracy" SG_ 1892 Minute1 "-";
BA_ "Accuracy" SG_ 1892 Minute2 "-";
BA_ "Accuracy" SG_ 1892 Month1 "-";
BA_ "Accuracy" SG_ 1892 Month2 "-";
BA_ "Accuracy" SG_ 1892 Year1 "-";
BA_ "Accuracy" SG_ 1892 Year2 "-";
BA_ "Accuracy" SG_ 1892 Year3 "-";
BA_ "Accuracy" SG_ 1892 Year4 "-";
BA_ "Accuracy" SG_ 1472 AverageFuelConsumptionAPlus "-";
BA_ "Event trans." SG_ 1472 AverageFuelConsumptionAPlus 0;
BA_ "GenSigSendType" SG_ 1472 AverageFuelConsumptionAPlus 3;
BA_ "Accuracy" SG_ 1472 AverageSpeedAPlus "-";
BA_ "Event trans." SG_ 1472 AverageSpeedAPlus 0;
BA_ "GenSigSendType" SG_ 1472 AverageSpeedAPlus 3;
BA_ "Accuracy" SG_ 1472 PartialOdometerAPlus "-";
BA_ "Event trans." SG_ 1472 PartialOdometerAPlus 0;
BA_ "GenSigSendType" SG_ 1472 PartialOdometerAPlus 3;
BA_ "Accuracy" SG_ 1472 ResetTripAPlusACK "-";
BA_ "Event trans." SG_ 1472 ResetTripAPlusACK 0;
BA_ "GenSigSendType" SG_ 1472 ResetTripAPlusACK 3;
BA_ "Accuracy" SG_ 1888 AutonomyDistance "-";
BA_ "Accuracy" SG_ 1888 InstantaneousFuelConsumption1 "-";
BA_ "Accuracy" SG_ 1888 InstantaneousFuelConsumption2 "-";
BA_ "Accuracy" SG_ 1888 InstantaneousFuelConsumption3 "-";
BA_ "Accuracy" SG_ 1888 TotalOdometer "-";
BA_ "Accuracy" SG_ 1476 AverageFuelConsumptionBPlus "-";
BA_ "Event trans." SG_ 1476 AverageFuelConsumptionBPlus 0;
BA_ "GenSigSendType" SG_ 1476 AverageFuelConsumptionBPlus 3;
BA_ "Accuracy" SG_ 1476 AverageSpeedBPlus "+/- 0,1";
BA_ "Event trans." SG_ 1476 AverageSpeedBPlus 0;
BA_ "GenSigSendType" SG_ 1476 AverageSpeedBPlus 3;
BA_ "Accuracy" SG_ 1476 PartialOdometerBPlus "+/- 0,1";
BA_ "Event trans." SG_ 1476 PartialOdometerBPlus 0;
BA_ "GenSigSendType" SG_ 1476 PartialOdometerBPlus 3;
BA_ "Accuracy" SG_ 1476 ResetTripBPlusACK "-";
BA_ "Event trans." SG_ 1476 ResetTripBPlusACK 0;
BA_ "GenSigSendType" SG_ 1476 ResetTripBPlusACK 3;
BA_ "Accuracy" SG_ 748 UConnReq "-";
BA_ "Event trans." SG_ 748 UConnReq 0;
BA_ "GenSigSendType" SG_ 748 UConnReq 6;
BA_ "Accuracy" SG_ 748 UConnReqAuthCode "-";
BA_ "Accuracy" SG_ 748 UConnReqFOBNum "-";
BA_ "Event trans." SG_ 1976 UConnSeed1 0;
BA_ "GenSigSendType" SG_ 1976 UConnSeed1 1;
BA_ "Event trans." SG_ 1976 UConnSeed2 0;
BA_ "GenSigSendType" SG_ 1976 UConnSeed2 1;
BA_ "Event trans." SG_ 1976 UConnSeed3 0;
BA_ "GenSigSendType" SG_ 1976 UConnSeed3 1;
BA_ "Event trans." SG_ 1976 UConnSeed4 0;
BA_ "GenSigSendType" SG_ 1976 UConnSeed4 1;
BA_ "Accuracy" SG_ 1452 DoorChimeBonnetReq "-";
BA_ "Event trans." SG_ 1452 DoorChimeBonnetReq 0;
BA_ "GenSigSendType" SG_ 1452 DoorChimeBonnetReq 3;
BA_ "Accuracy" SG_ 1452 DoorChimeHatchReq "-";
BA_ "Event trans." SG_ 1452 DoorChimeHatchReq 0;
BA_ "GenSigSendType" SG_ 1452 DoorChimeHatchReq 3;
BA_ "Accuracy" SG_ 1452 DoorChimeLFReq "-";
BA_ "Event trans." SG_ 1452 DoorChimeLFReq 0;
BA_ "GenSigSendType" SG_ 1452 DoorChimeLFReq 3;
BA_ "Accuracy" SG_ 1452 DoorChimeLRReq "-";
BA_ "Event trans." SG_ 1452 DoorChimeLRReq 0;
BA_ "GenSigSendType" SG_ 1452 DoorChimeLRReq 3;
BA_ "Accuracy" SG_ 1452 DoorChimeRFReq "-";
BA_ "Event trans." SG_ 1452 DoorChimeRFReq 0;
BA_ "GenSigSendType" SG_ 1452 DoorChimeRFReq 3;
BA_ "Accuracy" SG_ 1452 DoorChimeRRReq "-";
BA_ "Event trans." SG_ 1452 DoorChimeRRReq 0;
BA_ "GenSigSendType" SG_ 1452 DoorChimeRRReq 3;
BA_ "Accuracy" SG_ 1452 SBRChimeFrontRowSts "-";
BA_ "Event trans." SG_ 1452 SBRChimeFrontRowSts 0;
BA_ "GenSigSendType" SG_ 1452 SBRChimeFrontRowSts 3;
BA_ "Accuracy" SG_ 1452 SBRChimeRearRowSts "-";
BA_ "Event trans." SG_ 1452 SBRChimeRearRowSts 0;
BA_ "GenSigSendType" SG_ 1452 SBRChimeRearRowSts 3;
BA_ "Accuracy" SG_ 1452 SBRChimeType "-";
BA_ "Event trans." SG_ 1452 SBRChimeType 0;
BA_ "GenSigSendType" SG_ 1452 SBRChimeType 3;
BA_ "Event trans." SG_ 1452 SBRChimeVolume 0;
BA_ "GenSigSendType" SG_ 1452 SBRChimeVolume 3;
BA_ "Event trans." SG_ 1452 SBRFrontChimeRepetitionRate 0;
BA_ "GenSigSendType" SG_ 1452 SBRFrontChimeRepetitionRate 3;
BA_ "Event trans." SG_ 1452 SBRRearChimeRepetitionRate 0;
BA_ "GenSigSendType" SG_ 1452 SBRRearChimeRepetitionRate 3;
BA_ "GenSigStartValue" SG_ 992 VIN_MSG 3;
VAL_ 2000 AMP_DSS_STATSts 0 "CFG_ST" 1 "CFG_VID_SURR" 2 "CFG_AUD_SURR" 7 "SNA";
VAL_ 2000 AMP_MUTEDSts 1 "Muted" 0 "Unmuted";
VAL_ 2000 AUDIOSts_AMP 0 "Initialization" 1 "Available" 2 "Not_Available";
VAL_ 2000 PowerModeSts_AMP 0 "Standard_Power" 1 "Logistic_Mode_ON" 2 "Logistic_Mode_PR" 3 "Not_Used";
VAL_ 2000 SURR_AVAILSts 1 "TRUE" 0 "FALSE";
VAL_ 854 BonnetSts 0 "Closed" 1 "Open";
VAL_ 854 BrakeFluidLevelSts 0 "OK" 1 "Low_level";
VAL_ 854 BrakePadWearSts 0 "Not_Active" 1 "Active";
VAL_ 854 BrakePedalSwitchNOSts 0 "Not_Active" 1 "Active";
VAL_ 854 DoorLockLastElSts 0 "Locked" 1 "Driver_Door_Unlocked" 2 "All_Door_Unlocked" 3 "SNA";
VAL_ 854 DriverDoorSts 0 "Closed" 1 "Open";
VAL_ 854 ESLLockFailSts_Indication 0 "Not_Failure" 1 "Failure";
VAL_ 854 ESLUnlockFailSts_Indication 0 "Not_Failure" 1 "Failure";
VAL_ 854 FrontWiperMoveSts 0 "Stop" 1 "Moving";
VAL_ 854 FuelLevel 255 "SNA";
VAL_ 854 FuelLevelFailSts 0 "Fail_Not_Present" 1 "Fail_Present";
VAL_ 854 FWindShieldFailSts 0 "Not_active" 1 "Active";
VAL_ 854 LHRDoorSts 0 "Closed" 1 "Open";
VAL_ 854 LowFuelWarningSts 0 "OFF" 1 "ON";
VAL_ 854 MoveWheelSts 0 "Not_Active" 1 "Active";
VAL_ 854 NightAndDaySensorFailSts 0 "Fail_Not_Present" 1 "Fail_Present";
VAL_ 854 OperationalModeSts 0 "Initialization" 1 "Ignition_Off_WithoutKey" 2 "Ignition_Off" 3 "Ignition_Acc" 4 "Ignition_On" 5 "Ignition_Pre_Start" 6 "Ignition_Start" 7 "Ignition_Cranking" 8 "Ignition_On_EngOn" 9 "Ignition_Pre_Acc" 10 "Ignition_Pre_Off" 11 "Automatic_Cranking" 12 "Automatic_Stop" 13 "Key_Authenticated" 14 "Not_Used" 15 "SNA";
VAL_ 854 ParkBrakeSts 0 "OFF" 1 "ON";
VAL_ 854 PowerModeSts 0 "Standard_Power" 1 "Logistic_Mode_ON" 2 "Logistic_Mode_PR" 3 "LogisticModeON_and_EngineON";
VAL_ 854 PsngrDoorSts 0 "Closed" 1 "Open";
VAL_ 854 RainSensorFailSts 0 "Fail_not_present" 1 "Fail_present";
VAL_ 854 RearTrunkEnableLastElSts 0 "Disabled" 1 "Enabled";
VAL_ 854 RHatchSts 0 "Closed" 1 "Open";
VAL_ 854 RHRDoorSts 0 "Closed" 1 "Open";
VAL_ 854 SysEOLSts 0 "EOL_Ready" 1 "EOL_Not_Ready";
VAL_ 854 WarningKeyInSts 0 "Not_active" 1 "Active";
VAL_ 1132 BatteryChargeSts 15 "SNA";
VAL_ 1132 CmdIgn_FailSts 0 "Fail_Not_Present" 1 "Fail_Present" 3 "SNA";
VAL_ 1132 CmdIgnSts 0 "Initialization" 1 "IGN_LK" 3 "ACC" 4 "RUN" 5 "START" 7 "SNA";
VAL_ 1132 CurrentFailStsIBS 0 "No_DTC_Present_In_ECU" 1 "At_Least_One_DTC_Present_IN_ECU";
VAL_ 1132 DriveStyleSts 0 "Normal" 1 "City" 2 "Sport_Fun" 3 "Winter_Race" 4 "Eco" 5 "TracPlus" 6 "Trekking" 7 "Auto" 8 "Snow" 9 "Sand" 10 "Mud" 11 "Rock" 12 "Race" 31 "SNA";
VAL_ 1132 ExternalTemperatureC 511 "SNA";
VAL_ 1132 ExternalTemperatureF 511 "SNA";
VAL_ 1132 ExternalTemperatureFailSts 0 "Fail_Not_Present" 1 "Fail_Present";
VAL_ 1132 Int_Relay_FailSts 0 "Fail_Not_Present" 1 "Fail_Present" 3 "SNA";
VAL_ 1132 InternalLightLevel 0 "Level_1" 1 "Level_2" 2 "Level_3" 3 "Level_4" 4 "Level_5" 5 "Level_6" 6 "Level_7" 7 "Level_8" 8 "Level_9" 9 "Level_10" 10 "Level_11" 11 "Level_12" 12 "Level_13" 13 "Level_14" 14 "Level_15" 15 "Level_16";
VAL_ 1132 InternalLightSts 0 "Not_Active" 1 "Active";
VAL_ 1132 RemStActvSts 0 "Remote Start Not Active" 1 "Remote Start Active";
VAL_ 1132 TurnIndicationSts 0 "Center" 1 "Right" 2 "Left" 3 "SNA";
VAL_ 1128 ClusterLightSts 0 "Not_Active_Day" 1 "Active_Night";
VAL_ 1128 E_CALL_PSD 0 "Not_Pressed" 1 "Pressed";
VAL_ 1128 U_CALL_PSD 0 "Not_Pressed" 1 "Pressed";
VAL_ 988 LatAcceleration_BSM 4095 "SNA";
VAL_ 988 LatAccelerationFailSts_BSM 0 "Fail_Not_Present" 1 "Fail_Present";
VAL_ 988 LongAcceleration_BSM 4095 "SNA";
VAL_ 988 LongAccelerationFailSts_BSM 0 "Fail_Not_Present" 1 "Fail_Present";
VAL_ 988 Slope 255 "SNA";
VAL_ 988 YawRate_BSM 4095 "SNA";
VAL_ 988 YawRateFailSts_BSM 0 "Fail_Not_Present" 1 "Fail_Present";
VAL_ 990 LHF_FastPulseCounter 255 "SNA";
VAL_ 990 LHF_WheelSensorFailSts 0 "Fail_Not_Present" 1 "Fail_Present";
VAL_ 990 LHR_FastPulseCounter 255 "SNA";
VAL_ 990 LHR_WheelSensorFailSts 0 "Fail_Not_Present" 1 "Fail_Present";
VAL_ 990 RHF_FastPulseCounter 255 "SNA";
VAL_ 990 RHF_WheelSensorFailSts 0 "Fail_Not_Present" 1 "Fail_Present";
VAL_ 990 RHR_FastPulseCounter 255 "SNA";
VAL_ 990 RHR_WheelSensorFailSts 0 "Fail_Not_Present" 1 "Fail_Present";
VAL_ 990 TravelDistance 255 "SNA";
VAL_ 994 ACPressure 511 "SNA";
VAL_ 994 ACPressureFailSts 0 "Fail_Not_Present" 1 "Fail_Present";
VAL_ 994 AlternatorFail 0 "Alternator_Fail" 1 "Alternator_Not_In_Fail";
VAL_ 994 CompressorSts 0 "Not_Used" 1 "Not_inserted_by_NCM" 2 "Not_insrtd_by_driver_or_security" 3 "Inserted";
VAL_ 994 EngineSts 0 "Engine_Off" 1 "Engine_Cranking" 2 "Engine_On" 3 "SNA";
VAL_ 994 EngineWaterTemp 255 "SNA";
VAL_ 994 EngineWaterTempFailSts 0 "Fail_Not_Present" 1 "Fail_Present";
VAL_ 994 ESS_ENG_ST 1 "ENS Stopped" 2 "ENS Request Start" 3 "ENS Running" 4 "ENS Stop Pending" 5 "ENS Start protection" 6 "ENS Start inhibit" 7 "ENS disabled" 8 "ENS_IHB_LATCH" 9 "ENS Starting" 15 "SNA";
VAL_ 994 ShiftModeSts 0 "Manual" 1 "Automatic";
VAL_ 994 SpStSwStat 0 "OFF" 1 "CONT" 2 "BLINK" 3 "SNA";
VAL_ 994 VehicleSpeedVSOSig 8191 "SNA";
VAL_ 994 VehicleSpeedVSOSigFailSts 0 "Fail_not_present" 1 "Fail_present";
VAL_ 996 DPFSts 0 "Clean" 1 "Dirty";
VAL_ 996 FuelConsumption_GAG 65535 "SNA";
VAL_ 996 GearShiftIndication 0 "No_Gearshift_Suggestion_by_ECM" 1 "Downshift_Suggestion_by_ECM" 2 "Upshift_Suggestion_by_ECM" 3 "Strategy_Not_Available_ECM_Fail";
VAL_ 996 OilLifeSts 0 "Normal_Oil_Properties" 1 "Oil_Life_Reset" 2 "Change_Oil_Required" 3 "Not_used";
VAL_ 996 ReverseGearSts 0 "Not_Inserted" 1 "Inserted" 2 "Not_Used" 3 "SNA";
VAL_ 998 AFLM_Stat 0 "Disable" 1 "Enabled" 2 "Fault_HL_HS" 3 "SNA";
VAL_ 998 EngineSpeed 16383 "SNA";
VAL_ 998 EngineSpeedFailSts 0 "Fail_not_present" 1 "Fail_present";
VAL_ 998 EngineTorque 2047 "SNA";
VAL_ 998 EPBSts 0 "Released" 1 "Applied" 2 "DynamicBrkESC" 3 "DynamicBrkEPB" 4 "Emergency_Braking" 5 "Applying" 6 "Maintenance_Mode" 7 "Assembly_Check" 8 "Inspection_Mode" 9 "Re_Clamping" 10 "Adjuste_Mode" 11 "Releasing" 12 "Fault_EPB_Released" 13 "Fault_EPB_Applied" 14 "Fault_Present" 15 "SNA";
VAL_ 998 LWSAngle 65535 "SNA";
VAL_ 998 LWSFailSts 0 "Fail_not_Present" 1 "Fail_Present_Ignition_Latched" 2 "Fail_Present_Recoverable" 3 "Fail_Present_Battery_Disconnection";
VAL_ 998 ShiftLeverPosition 0 "No_Selection_Active_Or_Available" 1 "P" 2 "R" 3 "N" 4 "D" 5 "L" 6 "TIP_Autostick" 7 "Plus" 8 "Minus" 9 "Sport" 10 "Not_Used" 11 "Not_Used" 12 "Not_Used" 13 "Not_Used" 14 "Not_Used" 15 "SNA";
VAL_ 1984 InflationState_LHF_Tyre 0 "Normal_Tyre_Pressure" 1 "Under_Inflated_Tyre" 2 "SignificantlyUnderInflatedTyre" 3 "Over_Inflated_Tyre" 4 "Sensor_Missing";
VAL_ 1984 InflationState_LHR_Tyre 0 "Normal_Tyre_Pressure" 1 "Under_Inflated_Tyre" 2 "SignificantlyUnderInflatedTyre" 3 "Over_Inflated_Tyre" 4 "Sensor_Missing";
VAL_ 1984 InflationState_RHF_Tyre 0 "Normal_Tyre_Pressure" 1 "Under_Inflated_Tyre" 2 "SignificantlyUnderInflatedTyre" 3 "Over_Inflated_Tyre" 4 "Sensor_Missing";
VAL_ 1984 InflationState_RHR_Tyre 0 "Normal_Tyre_Pressure" 1 "Under_Inflated_Tyre" 2 "SignificantlyUnderInflatedTyre" 3 "Over_Inflated_Tyre" 4 "Sensor_Missing";
VAL_ 1984 PressureValue_LHF_Tyre 63 "SNA";
VAL_ 1984 PressureValue_LHR_Tyre 63 "SNA";
VAL_ 1984 PressureValue_RHF_Tyre 63 "SNA";
VAL_ 1984 PressureValue_RHR_Tyre 63 "SNA";
VAL_ 1984 TyrePressureSystemFailSts 0 "Fail_Not_Present" 1 "Fail_Present";
VAL_ 1000 ActualGearGSI 0 "Neutral" 1 "ForwardGear_1" 2 "ForwardGear_2" 3 "ForwardGear_3" 4 "ForwardGear_4" 5 "ForwardGear_5" 6 "ForwardGear_6" 7 "ReverseGear" 8 "ForwardGear_7" 9 "ForwardGear_8" 10 "ForwardGear_9" 15 "SNA";
VAL_ 1000 EngineOilLevel 0 "Level1" 1 "Level2" 2 "Level3" 3 "Level4" 4 "Level5" 5 "Level6" 6 "Level7" 7 "Level8" 8 "Level9" 9 "Level10" 10 "Level11" 11 "Level12" 12 "Level13" 13 "Level14" 31 "SNA";
VAL_ 1000 GasPedalAct 0 "Not_active" 1 "Active";
VAL_ 1000 GasPedalGradient 255 "SNA";
VAL_ 1000 GasPedalPosition 255 "SNA";
VAL_ 1000 GasPedalPositionFailSts 0 "Fail_not_present" 1 "Fail_present";
VAL_ 1000 GearEngaged 0 "Neutral" 1 "ForwardGear_1" 2 "ForwardGear_2" 3 "ForwardGear_3" 4 "ForwardGear_4" 5 "ForwardGear_5" 6 "ForwardGear_6" 7 "ForwardGear_7" 8 "ForwardGear_8" 9 "ForwardGear_9" 13 "Parking" 14 "ReverseGear" 15 "SNA";
VAL_ 1000 GearIndicationSts 0 "Normal" 1 "Blinking";
VAL_ 1130 A2D_DRV_TEMP_DR_POS 1023 "SNA";
VAL_ 1130 A2D_FT_HVAC_BLOWER_VOLTAGE 1023 "SNA";
VAL_ 1130 AcOutputCurrentSts 255 "SNA";
VAL_ 1130 CompressorACReqSts 0 "Not_Active" 1 "Active";
VAL_ 1130 HVAC_Blower_Speed 0 "0% <= PWM < 20%" 1 "20% <= PWM < 30%" 2 "30% <= PWM < 40%" 3 "40% <= PWM < 50%" 4 "50% <= PWM < 55%" 5 "55% <= PWM < 60%" 6 "60% <= PWM < 65%" 7 "65% <= PWM < 70%" 8 "70% <= PWM < 75%" 9 "75% <= PWM < 80%" 10 "80% <= PWM < 85%" 11 "85% <= PWM < 90%" 12 "90% <= PWM < 95%" 13 "95% <= PWM <= 100%" 14 "Blower_shutdown" 15 "SNA";
VAL_ 1130 HVAC_SAM_enable 0 "No_Request" 1 "SAM_Disabling_Request" 2 "Not Used" 3 "SNA";
VAL_ 1130 MaxDefrostSts 0 "OFF" 1 "ON";
VAL_ 1130 PowerModeSts_Climate 0 "Standard_Power" 1 "Logistic_Mode_On" 2 "Logistic_Mode_PR" 3 "Not_Used";
VAL_ 1130 PTCFailSts 0 "Fail_Not_Present" 1 "Fail_Present";
VAL_ 1130 PTCSts 0 "zero_per_cent" 1 "thirtythree_per_cent" 2 "sixtysix_per_cent" 3 "onehundred_per_cent";
VAL_ 1130 RHeatedWindowCmd 0 "Not_Active" 1 "Active";
VAL_ 1130 StopStartClimateInfo 0 "SPST_ON" 1 "CABIN_HI" 2 "CABIN_LO" 3 "MAX_AC" 4 "FT_DEFROST" 5 "EBL" 7 "SNA";
VAL_ 1130 StopStartEnable 0 "False" 1 "True";
VAL_ 1482 BlowerDisplay 0 "bar NOT Display" 1 "Bar_1" 2 "Bar_2 " 3 "Bar_3" 4 "Bar_4" 5 "Bar_5" 6 "Bar_6" 7 "Bar_7" 8 "Bar_8";
VAL_ 1482 DegreeUnit 0 "CELSIUS" 1 "FAHRENEIT";
VAL_ 1482 HeatedLeft 0 "OFF " 1 "LOW" 2 "MEDIUM" 3 "HIGH";
VAL_ 1482 HeatedRight 0 "OFF " 1 "LOW" 2 "MEDIUM" 3 "HIGH";
VAL_ 1482 ModeDefrostLeft 0 "OFF" 1 "Showed";
VAL_ 1482 ModeDefrostRight 0 "OFF" 1 "Showed";
VAL_ 1482 ModeFloorLeft 0 "OFF" 1 "Showed";
VAL_ 1482 ModeFloorRight 0 "OFF" 1 "Showed";
VAL_ 1482 ModeVentLeft 0 "OFF" 1 "Showed";
VAL_ 1482 ModeVentRight 0 "OFF" 1 "Showed";
VAL_ 1482 OFFSts 0 "ON" 1 "OFF";
VAL_ 1482 ShowHVACPopup 0 "No_Info_On_Display" 1 "Info_On_Display";
VAL_ 1482 SteeringHeatedCmd 0 "OFF" 1 "ON";
VAL_ 1482 TempLeftDisplay 1023 "SNA";
VAL_ 1482 TempRightDisplay 1023 "SNA";
VAL_ 1482 VentilatedLeft 0 "OFF " 1 "LOW" 2 "MEDIUM" 3 "HIGH";
VAL_ 1482 VentilatedRight 0 "OFF " 1 "LOW" 2 "MEDIUM" 3 "HIGH";
VAL_ 1482 WordingLeftDisplay 0 "OFF" 1 "T_req_display_Left" 2 "HI" 3 "LO";
VAL_ 1482 WordingRightDisplay 0 "OFF" 1 "T_req_display_Left" 2 "HI" 3 "LO";
VAL_ 1454 AUDIOSts_ESEM 0 "Not_Available" 1 "Available" 3 "SNA";
VAL_ 1454 PowerModeSts_ESEM 0 "Standard_Power" 1 "Logistic_Mode_ON" 2 "Logistic_Mode_PR";
VAL_ 1448 Ack_beep 0 "Not_Active" 1 "Active";
VAL_ 1448 DataCmdReady 0 "Not_Ready" 1 "Ready";
VAL_ 1448 MirrorDrvHorizzontalPosCmd 255 "SNA";
VAL_ 1448 MirrorDrvVerticalPosCmd 255 "SNA";
VAL_ 1448 MirrorPsngrHorizzontalPosCmd 255 "SNA";
VAL_ 1448 MirrorPsngrVerticalPosCmd 255 "SNA";
VAL_ 1098 BSS_LF_Chime_RQSts 0 "No_left_frnt_chime_on_req" 1 "Left_front_chime_on_req";
VAL_ 1098 BSS_LR_Chime_RQSts 0 "No_left_rear_chime_on_req" 1 "Left_rear_chime_on_req";
VAL_ 1098 BSS_LT_Blind_RQSts 0 "No Sensor Blocked Request" 1 "Sensor Blocked Request";
VAL_ 1098 BSS_LT_CFG_STATSts 0 "Not_enabled" 1 "Enabled_for_LED" 2 "Enabled_for_LED_and_Chime" 3 "SNA";
VAL_ 1098 BSS_LT_Chime_TypeSts 0 "None" 1 "type1" 2 "type2" 3 "type3" 4 "type4" 5 "type5" 6 "type6" 7 "type7" 8 "type8" 9 "type9" 10 "type10" 11 "type11" 12 "type12" 13 "type13" 14 "type14" 15 "SNA";
VAL_ 1098 BSS_LT_OPR_StatSts 0 "No Operational Failure" 1 "Operational Failure - System Unavailable";
VAL_ 1098 BSS_LT_SRV_RQSts 0 "No Service Request" 1 "Service Request";
VAL_ 1098 BssLtLedFaultSts 0 "No_Fault" 1 "Short_to_Ground" 2 "Short_to_Batt" 3 "Open_Circuit";
VAL_ 1098 BssLtWrnSts 0 "Not_Present" 1 "Present";
VAL_ 1462 DynamicGridFailSts 0 "Fail_Not_Present" 1 "Fail_Present";
VAL_ 1462 DynamicGridSts 0 "Dynamic Gridlines OFF" 1 "Dynamic Gridlines ON";
VAL_ 1462 StW_TempSensSts 0 "NormalOperation_OK" 1 "SWTemp_ SensorShortCircuit_SHRT" 2 "SWTemp_SensorOpenCircuit_OPN" 3 "SNA";
VAL_ 1462 StW_TempSts 255 "SNA";
VAL_ 1462 SWSError 0 "No_Errors" 1 "Error_Present";
VAL_ 1446 MirrorDrvHorizzontalPosSts 255 "SNA";
VAL_ 1446 MirrorDrvStandStillSts 0 "StandStill" 1 "Moving";
VAL_ 1446 MirrorDrvVerticalPosSts 255 "SNA";
VAL_ 1446 MirrorPsngrHorizzontalPosSts 255 "SNA";
VAL_ 1446 MirrorPsngrStandStillSts 0 "StandStill" 1 "Moving";
VAL_ 1446 MirrorPsngrVerticalPosSts 255 "SNA";
VAL_ 1268 FrontSensorSts 0 "Active" 1 "Not_Active_blocked" 2 "Not_Active_failure" 3 "SNA";
VAL_ 1268 PAMSystemFault 0 "False" 1 "Temporary_Failure" 2 "External_Failure" 3 "System_Failure";
VAL_ 1268 PAMSystemSts 0 "OFF" 1 "ON_Active" 2 "ON_Inactive" 3 "ON_Disabled";
VAL_ 1268 RearSensorSts 0 "Active" 1 "Not_Active_blocked" 2 "Not_Active_failure" 3 "SNA";
VAL_ 1100 BSS_RF_Chime_RQSts 0 "No_rght_frnt_chime_on_req" 1 "Right_front_chime_on_req";
VAL_ 1100 BSS_RR_Chime_RQSts 0 "No_rght_rear_chime_on_req" 1 "Right_rear_chime_on_req";
VAL_ 1100 BSS_RT_Blind_RQSts 0 "No Sensor Bocked Request" 1 "Sensor Blocked Request";
VAL_ 1100 BSS_RT_CFG_STATSts 0 "Not_enabled" 1 "Enabled_for_LED" 2 "Enabled_for_LED_and_Chime" 3 "SNA";
VAL_ 1100 BSS_RT_Chime_TypeSts 0 "None" 1 "type1" 2 "type2" 3 "type3" 4 "type4" 5 "type5" 6 "type6" 7 "type7" 8 "type8" 9 "type9" 10 "type10" 11 "type11" 12 "type12" 13 "type13" 14 "type14" 15 "SNA";
VAL_ 1100 BSS_RT_OPR_StatSts 0 "No Operational Failure" 1 "Operational failure - System Unavailable";
VAL_ 1100 BSS_RT_SRV_RQSts 0 "No Service Requested" 1 "Service Requested";
VAL_ 1100 BssRtLedFaultSts 0 "No_Fault" 1 "Short_to_Ground" 2 "Short_to_Batt" 3 "Open_Circuit";
VAL_ 1100 BssRtWrnSts 0 "Not_Present" 1 "Present";
VAL_ 1458 ConnectivityStatus 0 "Initialization" 1 "Connectivity_Disabled" 2 "Connectivity_Enabled" 3 "SNA";
VAL_ 1458 PowerModeSts_TBM 0 "Standard_Power" 1 "Logistic_Mode_On" 2 "Logistic_Mode_PR" 3 "Not_Used";
VAL_ 1458 RemoteUpdateStatus 0 "No_Active_Update" 1 "Update_On_Going" 2 "Update_Ended";
VAL_ 1458 SOSCallStatus 0 "No_Indication" 1 "Sos_Battery_Fail" 2 "Sos_Fail" 3 "Sos_Call_Ended" 4 "Sos_Call_Establish" 5 "Starting_SOS_Fail" 6 "Incoming_SOS_Call" 7 "Starting_SOS_1_Phase" 8 "Starting_SOS_2_Phase" 9 "Starting_SOS_Auto";
VAL_ 1458 SOSCallType 0 "Initialization" 1 "No_active_SOS_call" 2 "Manual_SOS_call" 3 "Automatic_SOS_call" 4 "Callback_SOS_call" 5 "Callback_wait" 7 "SNA";
VAL_ 1470 AntitheftSts 0 "Not_Successfully" 1 "In_Progress" 2 "Successfully";
VAL_ 1470 AUDIOSts_Telematic 0 "Initialization" 1 "Available" 2 "Not_Available";
VAL_ 1470 CurrentSource 0 "AM_Selected" 1 "FM_Selected" 2 "MW_Selected" 3 "LW_Selected" 4 "Internal_DISC_Selected" 5 "Internal_HDD_Selected" 6 "Internal_AUX_Selected" 7 "Internal_Slot_Media_Slctd" 8 "DTV_Selected" 9 "SDAR1_Selected" 10 "SW_Selected" 11 "VES_DVD1_Selected" 12 "MFLO_Selected" 13 "VES_AUX1_Selected" 14  "VES_AUX2_Selected" 15 "SDARV_Selected" 16 "HFM_Personal_HU_Selected" 18 "DAB_Selected" 19 "TGW_USB1_Selected" 23 "HFM_BlueTooth_1_Selected" 28 "IR_Off_Selected" 29 "HU_Off " 30 "HU_Locked" 31 "SNA";
VAL_ 1470 E_CALL_STAT 0 "Off" 1 "Continuous_Light" 2 "Blinking_Light" 3 "SNA";
VAL_ 1470 HFPSts 0 "Not_Active" 1 "Pending" 2 "Active";
VAL_ 1470 MuteSts 0 "Not_Muted" 1 "Muted";
VAL_ 1470 Popup_Feedback 0 "No_Info" 1 "Partial_Screen" 2 "Extended_Screen";
VAL_ 1470 PowerModeSts_Telematic 0 "Standard_Power" 1 "Logistic_Mode_ON" 2 "Logistic_Mode_PR" 3 "Not_Used";
VAL_ 1470 PowerSts_Telematic 0 "Sleep" 1 "Standby" 2 "Timed" 3 "Idle" 4 "Full_Operation" 5 "Logistic_On" 6 "Bench";
VAL_ 1470 U_CALL_STAT 0 "Off" 1 "Continuous_Light" 2 "Blinking_Light" 3 "SNA";
VAL_ 1470 VRSts 0 "Not_Active" 1 "Active";
VAL_ 1464 TrailerConnectionSts 0 "Not_Connected" 1 "Connected" 2 "Not_Used" 3 "SNA";
VAL_ 1464 TrailerGenericFailSts 0 "No_fault_present" 1 "Fault_present";
VAL_ 1464 TrailerLHParkingLightFailSts 0 "No_fault_present" 1 "Fault_present";
VAL_ 1464 TrailerLHParkingLightSts 0 "OFF" 1 "ON";
VAL_ 1464 TrailerLHTurnSignalFailSts 0 "No_fault_present" 1 "Fault_present";
VAL_ 1464 TrailerLHTurnSignalSts 0 "OFF" 1 "ON";
VAL_ 1464 TrailerRearFogLightFailSts 0 "No_fault_present" 1 "Fault_present";
VAL_ 1464 TrailerRearFogLightSts 0 "OFF" 1 "ON";
VAL_ 1464 TrailerReverseGearFailSts 0 "No_fault_present" 1 "Fault_present";
VAL_ 1464 TrailerReverseGearSts 0 "OFF" 1 "ON";
VAL_ 1464 TrailerRHParkingLightFailSts 0 "No_fault_present" 1 "Fault_present";
VAL_ 1464 TrailerRHParkingLightSts 0 "OFF" 1 "ON";
VAL_ 1464 TrailerRHTurnSignalFailSts 0 "No_fault_present" 1 "Fault_present";
VAL_ 1464 TrailerRHTurnSignalSts 0 "OFF" 1 "ON";
VAL_ 1464 TrailerStopLightFailSts 0 "No_fault_present" 1 "Fault_present";
VAL_ 1464 TrailerStopLightSts 0 "OFF" 1 "ON";
VAL_ 750 Command_01Sts 0 "Not_Pressed" 1 "Pressed" 3 "SNA";
VAL_ 750 Command_02Sts 0 "Not_Pressed" 1 "Pressed" 3 "SNA";
VAL_ 750 Command_03Sts 0 "Not_Pressed" 1 "Pressed" 3 "SNA";
VAL_ 750 Command_04Sts 0 "Not_Pressed" 1 "Pressed" 3 "SNA";
VAL_ 750 Command_05Sts 0 "Not_Pressed" 1 "Pressed" 3 "SNA";
VAL_ 750 Knob_Encoder_CMD_Dir 0 "Knob_No_Change" 1 "Knob_Incremental_Clockwise" 2 "Knob_Decremental" 4 "Knob_Enter";
VAL_ 144 FrameNumber 0 "Frame1" 1 "Frame2" 2 "Frame3" 3 "Frame4" 4 "Frame5" 5 "Frame6" 6 "Frame7" 7 "Frame8" 8 "Frame9" 9 "Frame10" 10 "Frame11" 11 "Frame12" 12 "Frame13" 13 "Frame14" 14 "Frame15" 15 "Frame16" 16 "Frame17" 17 "Frame18" 18 "Frame19" 19 "Frame20" 20 "Frame21" 21 "Frame22" 22 "Frame23" 23 "Frame24" 24 "Frame25" 25 "Frame26" 26 "Frame27" 27 "Frame28" 28 "Frame29" 29 "Frame30" 30 "Frame31" 31 "Frame32";
VAL_ 144 TotalFrameNumber 0 "Frame1" 1 "Frame2" 2 "Frame3" 3 "Frame4" 4 "Frame5" 5 "Frame6" 6 "Frame7" 7 "Frame8" 8 "Frame9" 9 "Frame10" 10 "Frame11" 11 "Frame12" 12 "Frame13" 13 "Frame14" 14 "Frame15" 15 "Frame16" 16 "Frame17" 17 "Frame18" 18 "Frame19" 19 "Frame20" 20 "Frame21" 21 "Frame22" 22 "Frame23" 23 "Frame24" 24 "Frame25" 25 "Frame26" 26 "Frame27" 27 "Frame28" 28 "Frame29" 29 "Frame30" 30 "Frame31" 31 "Frame32";
VAL_ 752 AccelerationIndex 15 "SNA";
VAL_ 752 DecelerationIndex 15 "SNA";
VAL_ 752 FuelTargetMAX 65535 "SNA";
VAL_ 752 FuelTargetMIN 65535 "SNA";
VAL_ 752 GearIndex 15 "SNA";
VAL_ 752 SpeedIndex 15 "SNA";
VAL_ 136 LastAnnouncement 0 "Not_Last" 1 "Last";
VAL_ 136 ResolutionDistToTurn 0 "One" 1 "ZeroPointOne" 2 "ZeroPointZeroOne";
VAL_ 136 Unit 0 "ClearUnit" 1 "Kilometer" 2 "Meter" 3 "Mile" 4 "Feet" 5 "Yard" 6 "SNA";
VAL_ 158 AmbientLightingLevel_Req 0 "Level_1" 1 "Level_2" 2 "Level_3" 3 "Level_4" 4 "Level_5" 5 "Level_6" 6 "Level_7" 7 "Level_8" 8 "Level_9" 9 "Level_10" 10 "Level_11" 11 "Level_12" 12 "Level_13" 13 "Level_14" 14 "Level_15" 15 "Level_16";
VAL_ 158 AudioRepetition_Req 0 "On" 1 "Off";
VAL_ 158 AutoHighBeamEnable_Req 0 "Not_Enable" 1 "Enable";
VAL_ 158 AutomaticResetTripB_Req 0 "Never" 1 "Always" 2 "2 hours" 3 "8 hours";
VAL_ 158 AutoParkBrake_Req 0 "On" 1 "Off";
VAL_ 158 AutoRelock_Req 0 "Disable" 1 "Enable";
VAL_ 158 BSDEnable_Req 0 "Not_Enable" 1 "Enable_LED" 2 "Enable_ LED_Chime";
VAL_ 158 ConsumptionUnit_Req 0 "Km_Per_Litre" 1 "Litres_Per_100Km" 2 "Miles_Per_Gallon_UK" 3 "Miles_Per_Gallon_US" 4 "not_used" 5 "not_used" 6 "not_used" 7 "not_used";
VAL_ 158 CorneringEnable_Req 0 "True" 1 "False";
VAL_ 158 DistanceUnit_Req 0 "km" 1 "miles";
VAL_ 158 DRLEnable_Req 0 "True" 1 "False";
VAL_ 158 DynamicGrid_Req 0 "Dynamic Gridlines OFF" 1 "Dynamic Gridlines ON";
VAL_ 158 ExternalLightSensorLevel_Req 0 "Level_3" 1 "Level_2" 2 "Level_1" 3 "Level_0";
VAL_ 158 GreetingLightsEnable_Req 0 "True" 1 "False";
VAL_ 158 HourMode_Req 0 "0_24_h" 1 "0_12_h";
VAL_ 158 LanguageSelection_Req 0 "Italian" 1 "Deutsch" 2 "English" 3 "Espanol" 4 "Francais" 5 "Portugues" 6 "Polish" 7 "Dutch" 8 "Brazilian" 9 "Turkish" 10 "Mexican" 11 "English_US" 12 "Canadian" 13 "Russian" 14 "Chinese" 15 "Japanese" 16 "Korean" 17 "Arabic";
VAL_ 158 NavigationRepetition_Req 0 "On" 1 "Off";
VAL_ 158 PamAlertMode_Req 0 "Off" 1 "Sound" 2 "Sound_Display";
VAL_ 158 PamChimeVolumeFront_Req 0 "Low" 1 "Medium" 2 "High";
VAL_ 158 PamChimeVolumeRear_Req 0 "Low" 1 "Medium" 2 "High";
VAL_ 158 PassiveEntry_Req 0 "On" 1 "Off";
VAL_ 158 PhoneRepetition_Req 0 "On" 1 "Off";
VAL_ 158 RemoteDoorUnlock_Req 0 "Driver" 1 "All";
VAL_ 158 ResetTripA_Req 0 "Not_Active" 1 "Active";
VAL_ 158 ResetTripB_Req 0 "Not_Active" 1 "Active";
VAL_ 158 SoundHornLock_Req 0 "Off" 1 "1st Press" 2 "2nd Press";
VAL_ 158 SoundHornRemoteStart_Req 0 "On" 1 "Off";
VAL_ 158 SpeedLockDoorEnable_Req 0 "Not_Enable" 1 "Enable";
VAL_ 158 TemperatureUnit_Req 0 "°C" 1 "°F";
VAL_ 158 Trip_B_Enable_Req 0 "Not_Enable" 1 "Enable";
VAL_ 162 AutoUnlockDoorExit_Req 0 "Not_Enable" 1 "Enable";
VAL_ 162 BrakeService_Req 0 "Disable" 1 "Enable";
VAL_ 162 BuzzerVolume_Req 0 "Low" 1 "Mid" 2 "High" 3 "Not_Used";
VAL_ 162 CalibrationSetup_Req 0 "Disable" 1 "Enable";
VAL_ 162 EPB_MaintenanceMode_Req 0 "Off" 1 "On";
VAL_ 162 FlashLightWLock_Req 0 "Off" 1 "On";
VAL_ 162 FrontPassengerAirBag_Req 0 "Not_Request" 1 "Disable" 2 "Enable" 3 "SNa";
VAL_ 162 FSFCWPlusActivationMode_Req 0 "Near" 1 "Med" 2 "Far";
VAL_ 162 FSFCWPlusSetting_Req 0 "Off" 1 "Audio" 2 "Brake" 3 "Audio_Brake" 4 "Not_Request";
VAL_ 162 HeadlightsOffDelay_Req 0 "0sec" 1 "30sec" 2 "60sec" 3 "90sec";
VAL_ 162 HHDisabling_Req 0 "Disable" 1 "Enable";
VAL_ 162 LDW_Sensibility_Req 0 "Early" 1 "Med" 2 "Late";
VAL_ 162 SeatBeltReminder_Req 0 "Disable" 1 "Enable";
VAL_ 162 SpeedLimitSts_Req 0 "Disable" 1 "Enable";
VAL_ 162 TyrePressureUnit_Req 0 "kPa" 1 "psi" 2 "bar";
VAL_ 162 Units_Req 0 "US" 1 "Imperial" 2 "Metric" 3 "Custom";
VAL_ 1472 AverageFuelConsumptionAPlus 1023 "SNA";
VAL_ 1472 AverageSpeedAPlus 255 "SNA";
VAL_ 1472 PartialOdometerAPlus 1048575 "SNA";
VAL_ 1472 ResetTripAPlusACK 0 "No_ACK_required" 1 "ACK_KO" 2 "ACK_KO" 3 "ACK_OK";
VAL_ 1888 AutonomyDistance 2047 "SNA";
VAL_ 1888 InstantaneousFuelConsumption1 15 "SNA";
VAL_ 1888 InstantaneousFuelConsumption2 15 "SNA";
VAL_ 1888 InstantaneousFuelConsumption3 15 "SNA";
VAL_ 1476 AverageFuelConsumptionBPlus 1023 "SNA";
VAL_ 1476 AverageSpeedBPlus 255 "SNA";
VAL_ 1476 PartialOdometerBPlus 1048575 "SNA";
VAL_ 1476 ResetTripBPlusACK 0 "No_ACK_required" 1 "ACK_KO" 2 "ACK_KO" 3 "ACK_OK";
VAL_ 748 UConnReq 0 "NO_BASIC_REQUEST" 1 "LOCK_REQUEST" 2 "RELOCK_REQUEST" 3 "DRIVER_UNLOCK_REQUEST" 4 "ALL_UNLOCK_REQUEST" 5 "TRUNK_PLG_TOGGLE_REQUEST" 6 "LEFT_SLIDER_TOGGLE_REQUEST" 7 "RIGHT_SLIDER_TOGGLE_REQUEST" 8 "FLIPPER_GLASS_REQUEST" 9 "REMOTE_START_ON" 10 "REMOTE_START_OFF" 11 "GLOBAL_WINDOW_DOWN_REQUEST" 12 "OPEN_CONVERTIBLE_TOP" 13 "CLOSE_CONVERTIBLE_TOP" 14 "PANIC_TOGGLE_REQUEST" 31 "SNA";
VAL_ 748 UConnReqFOBNum 0 "FOB_DEFAULT" 1 "FOB_1" 2 "FOB_2" 3 "FOB_3" 4 "FOB_4" 5 "FOB_5" 6 "FOB_6" 7 "FOB_7" 8 "FOB_8" 15 "SNA";
VAL_ 1452 DoorChimeBonnetReq 0 "Idle" 1 "Active" 2 "Disactive";
VAL_ 1452 DoorChimeHatchReq 0 "Idle" 1 "Active" 2 "Disactive";
VAL_ 1452 DoorChimeLFReq 0 "Idle" 1 "Active" 2 "Disactive";
VAL_ 1452 DoorChimeLRReq 0 "Idle" 1 "Active" 2 "Disactive";
VAL_ 1452 DoorChimeRFReq 0 "Idle" 1 "Active" 2 "Disactive";
VAL_ 1452 DoorChimeRRReq 0 "Idle" 1 "Active" 2 "Disactive";
VAL_ 1452 SBRChimeFrontRowSts 0 "Idle" 1 "Active" 2 "Disactive";
VAL_ 1452 SBRChimeRearRowSts 0 "Idle" 1 "Active" 2 "Disactive";
VAL_ 1452 SBRChimeType 0 "Type_1" 1 "Type_2" 2 "Type_3" 3 "Type_4";
VAL_ 1452 SBRChimeVolume 0 "Level1" 1 "Level2" 2 "Level3" 3 "Level4" 4 "Level5" 5 "Level6" 6 "Level7" 7 "Level8";
VAL_ 1452 SBRFrontChimeRepetitionRate 0 "Rate1" 1 "Rate2" 2 "Rate3" 3 "Rate4" 4 "Rate5" 5 "Rate6" 6 "Rate7" 7 "Rate8";
VAL_ 1452 SBRRearChimeRepetitionRate 0 "Rate1" 1 "Rate2" 2 "Rate3" 3 "Rate4" 4 "Rate5" 5 "Rate6" 6 "Rate7" 7 "Rate8";
VAL_ 992 VIN_MSG 0 "VIN_LO" 1 "VIN_MID" 2 "VIN_HI" 3 "SNA";
